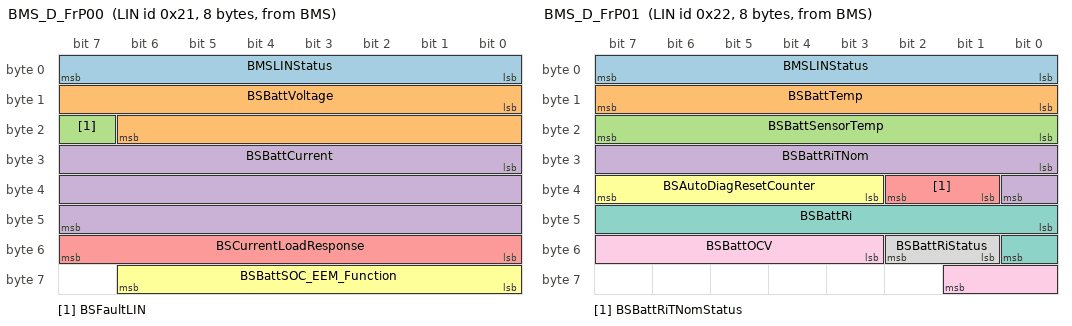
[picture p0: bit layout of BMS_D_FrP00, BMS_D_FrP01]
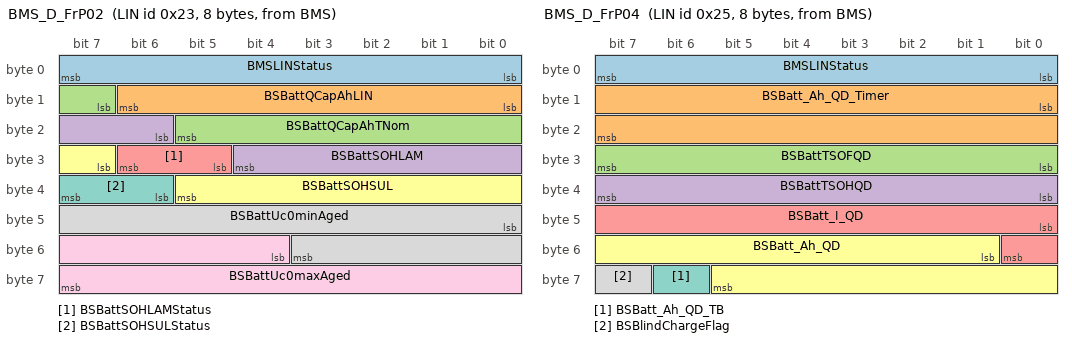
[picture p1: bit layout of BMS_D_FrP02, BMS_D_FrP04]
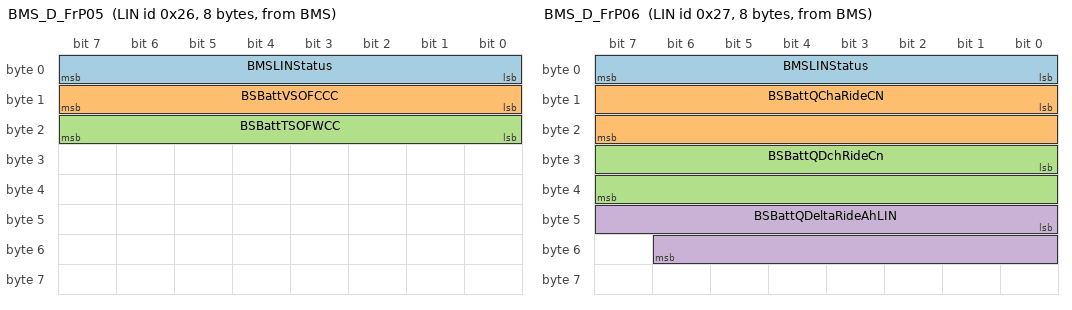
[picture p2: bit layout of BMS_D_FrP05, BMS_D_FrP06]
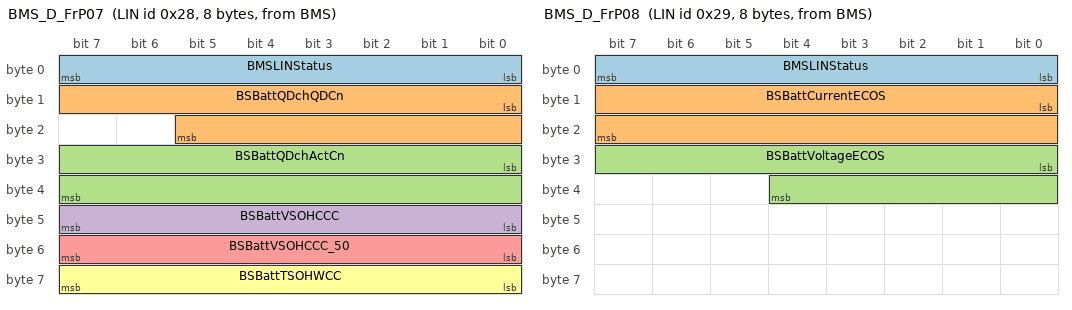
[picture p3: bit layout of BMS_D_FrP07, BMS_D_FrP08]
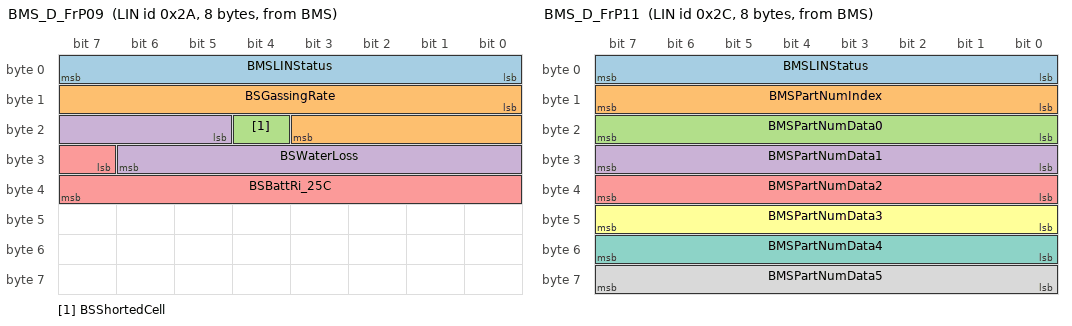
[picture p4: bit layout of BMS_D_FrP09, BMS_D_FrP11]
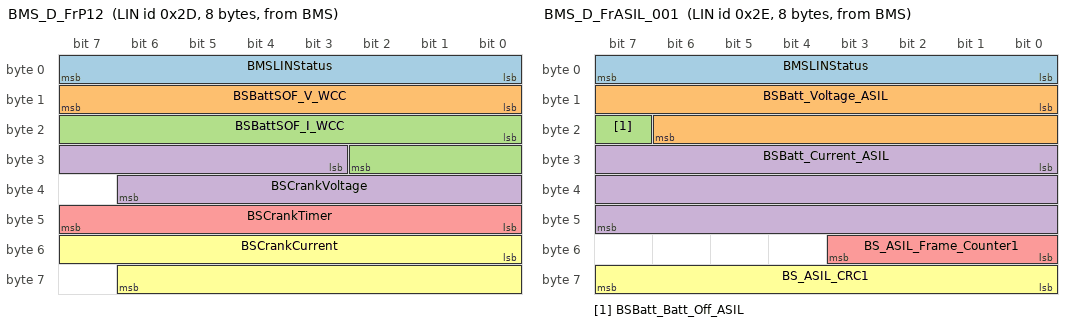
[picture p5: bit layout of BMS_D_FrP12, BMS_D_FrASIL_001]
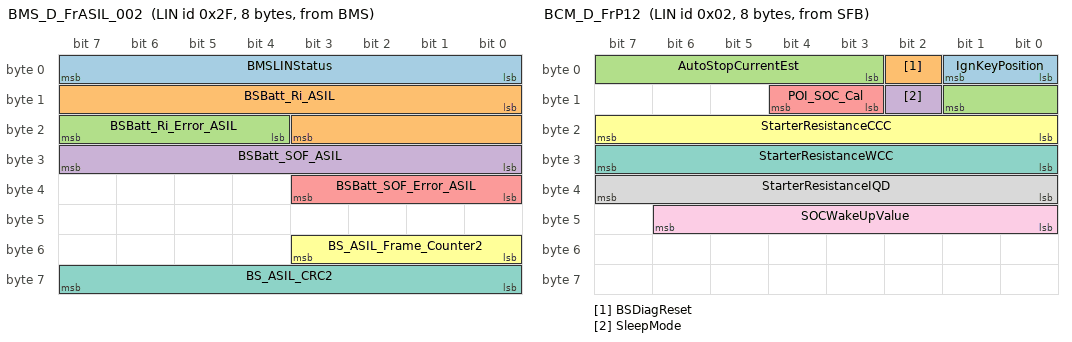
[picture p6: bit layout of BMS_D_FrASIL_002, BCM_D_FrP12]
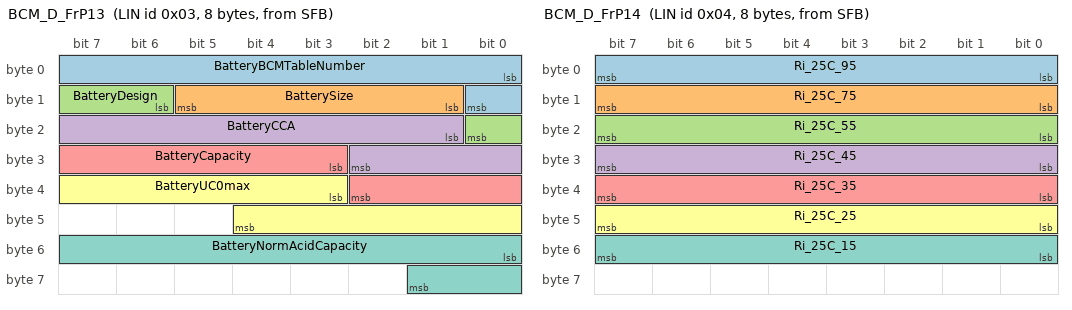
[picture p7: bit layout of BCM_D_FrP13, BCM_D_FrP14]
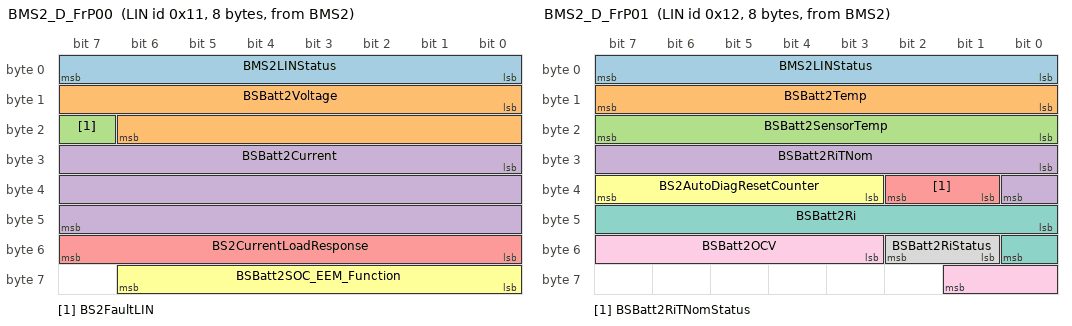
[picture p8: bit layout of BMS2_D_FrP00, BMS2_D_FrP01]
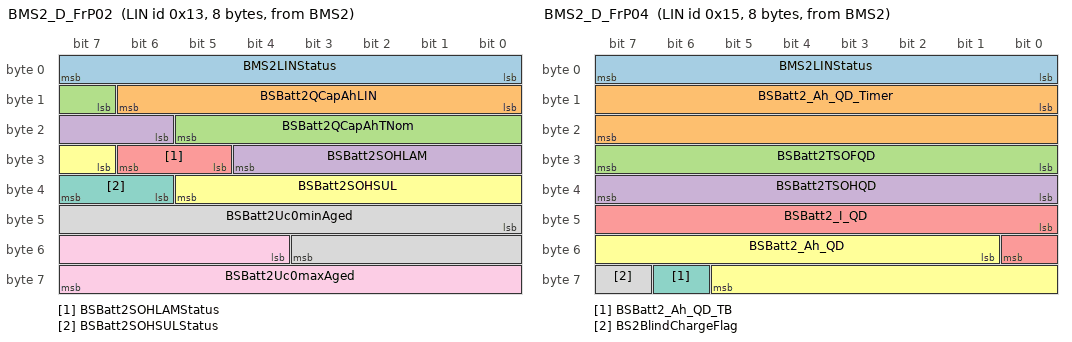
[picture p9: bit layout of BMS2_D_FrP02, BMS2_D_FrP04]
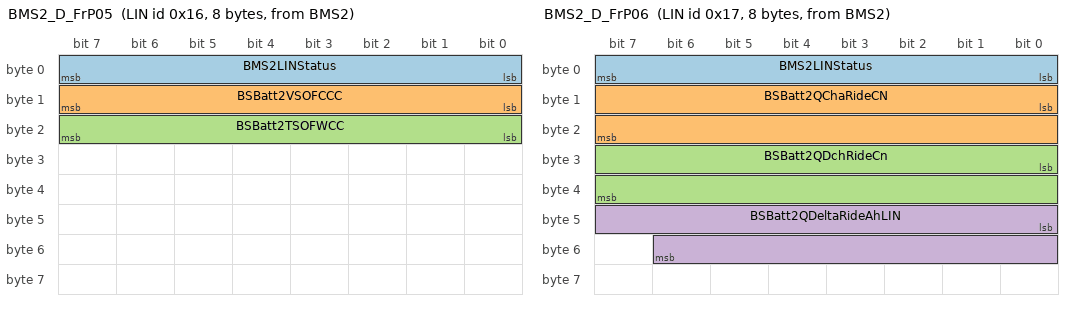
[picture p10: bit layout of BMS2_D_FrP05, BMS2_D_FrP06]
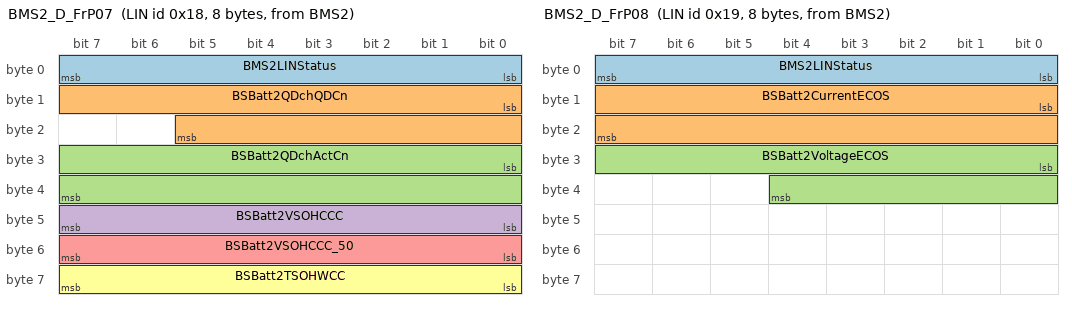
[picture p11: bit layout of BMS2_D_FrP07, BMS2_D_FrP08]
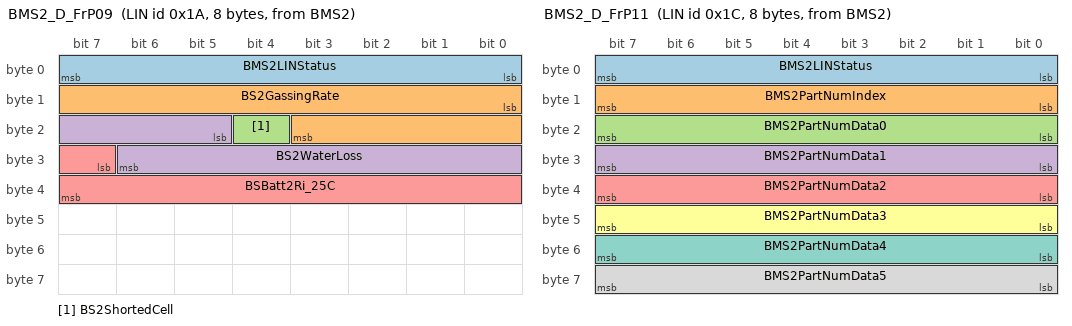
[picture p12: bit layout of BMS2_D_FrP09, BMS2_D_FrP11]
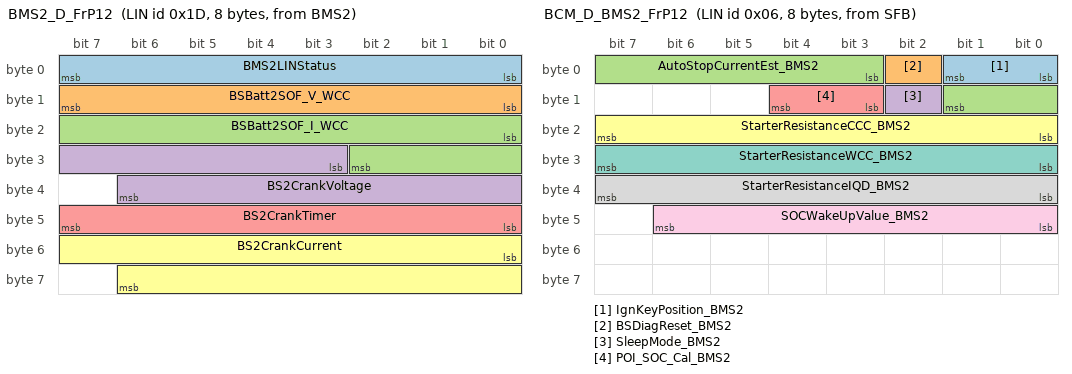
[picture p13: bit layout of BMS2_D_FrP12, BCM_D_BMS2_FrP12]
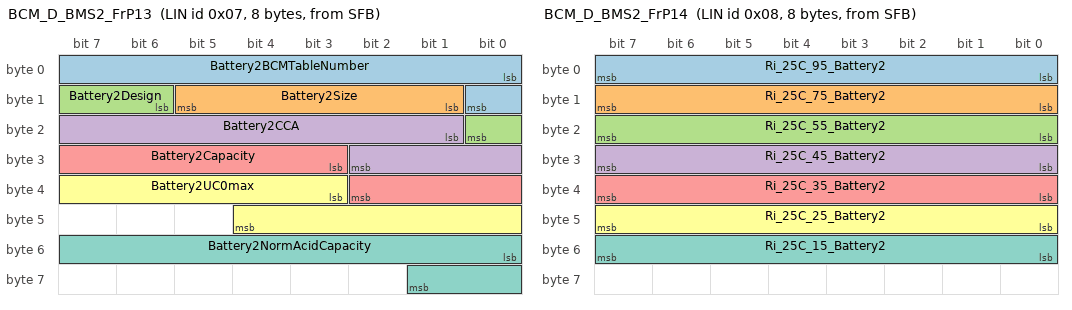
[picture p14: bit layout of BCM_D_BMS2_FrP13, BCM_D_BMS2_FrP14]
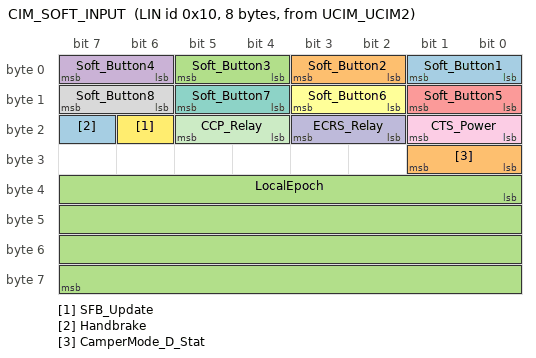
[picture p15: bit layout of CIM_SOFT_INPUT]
/* Azura Engineering Ltd */
/* All rights reserved */
/* Description: LIN Description file */
/* Date Created: 01-Nov-2023 */
/* Author: richard.harvie@azura-engineering.com */
/* Project: SFB Split Charge */
/* Release: Version 01 */
/* Configuration: SFB BMS2 BMS3 UCIM_UCIM2 */
/* Network: Private LIN BUS */
/* Original File: Ford BCM_LIN_D_Ckt_2021Apr08.ldf */

LIN_description_file;
LIN_protocol_version = "J2602_1_1.0";
LIN_language_version = "J2602_3_1.0";
LIN_speed = 10.417 kbps;

Nodes {
  Master: SFB, 10 ms, 0.05 ms;
  Slaves: BMS, BMS2, UCIM_UCIM2 ;
}

Signals {
   // Name, Size(bits), InitVal(raw), Publisher, Subscriber(s)

   /******** BMS -> Master ********/
   /* -= BMSLINStatus =- */
  BMSLINStatus: 8, 0, BMS, SFB ;
   /* -= Signals of BMS_D_FrP00 =- */
  BSBattVoltage: 15, 13120, BMS, SFB ;
  BSFaultLIN: 1, 0, BMS, SFB ;
  BSBattCurrent: 24, {0, 0, 2}, BMS, SFB ;
  BSCurrentLoadResponse: 8, 0, BMS, SFB ;
   /* -= Signals of BMS_D_FrP01 =- */
  BSBattTemp: 8, 60, BMS, SFB ;
  BSBattSensorTemp: 8, 60, BMS, SFB ;
  BSBattRiTNom: 9, 80, BMS, SFB ;
  BSBattRiTNomStatus: 2, 1, BMS, SFB ;
  BSAutoDiagResetCounter: 5, 0, BMS, SFB ;
  BSBattRi: 9, 80, BMS, SFB ;
  BSBattRiStatus: 2, 1, BMS, SFB ;
  BSBattOCV: 7, 104, BMS, SFB ;
   /* -= Signals of BMS_D_FrP02 =- */
  BSBattQCapAhLIN: 7, 60, BMS, SFB ;
  BSBattQCapAhTNom: 7, 60, BMS, SFB ;
  BSBattSOHLAM: 7, 0, BMS, SFB ;
  BSBattSOHLAMStatus: 2, 0, BMS, SFB ;
  BSBattSOHSUL: 7, 0, BMS, SFB ;
  BSBattSOHSULStatus: 2, 0, BMS, SFB ;
  BSBattUc0minAged: 12, 3036, BMS, SFB ;
  BSBattUc0maxAged: 12, 3297, BMS, SFB ;
   /* -= Signals of BMS_D_FrP03 =- */
  BSBattSOC_Actual: 7, 75, BMS, SFB ;
  BSBattSOC_EEM_Function: 7, 75, BMS, SFB ;
  BSBattSOCStatus: 2, 3, BMS, SFB ;
  BSBattLastSOCRecal: 8, 0, BMS, SFB ;
  BSBattSOCRecalUsed: 2, 3, BMS, SFB ;
  BSBattSOC_AhFlag: 1, 0, BMS, SFB ;
  BSBattSOC_ConsistencyFlag: 1, 0, BMS, SFB ;
  BSBattSOC_BlindChargeFlag: 1, 0, BMS, SFB ;
  BSBattSOC_PORFlag: 1, 1, BMS, SFB ;
  BSBattSOC_BSFaultFlag: 1, 0, BMS, SFB ;
  BSBattSOC_BatteryParameters: 1, 0, BMS, SFB ;
  BSBattSOC_BSDiagResetFlag: 1, 0, BMS, SFB ;
  BSBattSOC_TransportFlag: 1, 0, BMS, SFB ;
  BSStratification: 1, 0, BMS, SFB ;
  BSIcing: 1, 0, BMS, SFB ;
  BSConsistencyFault: 1, 0, BMS, SFB ;
  BSPowerOnJustOccured: 1, 1, BMS, SFB ;
  BSBattFullChargeDetected: 1, 0, BMS, SFB ;
  BSMode: 1, 0, BMS, SFB ;
  BSBattTimeInService: 12, 0, BMS, SFB ;
   /* -= Signals of BMS_D_FrP04 =- */
  BSBatt_Ah_QD_Timer: 16, 0, BMS, SFB ;
  BSBattTSOFQD: 8, 60, BMS, SFB ;
  BSBattTSOHQD: 8, 60, BMS, SFB ;
  BSBatt_I_QD: 9, 30, BMS, SFB ;
  BSBatt_Ah_QD: 13, 0, BMS, SFB ;
  BSBatt_Ah_QD_TB: 1, 0, BMS, SFB ;
  BSBlindChargeFlag: 1, 0, BMS, SFB ;
   /* -= Signals of BMS_D_FrP05 =- */
  BSBattVSOFCCC: 8, 176, BMS, SFB ;
  BSBattTSOFWCC: 8, 255, BMS, SFB ;
   /* -= Signals of BMS_D_FrP06 =- */
  BSBattQChaRideCN: 16, 0, BMS, SFB ;
  BSBattQDchRideCn: 16, 0, BMS, SFB ;
  BSBattQDeltaRideAhLIN: 15, 12800, BMS, SFB ;
   /* -= Signals of BMS_D_FrP07 =- */
  BSBattQDchQDCn: 14, 0, BMS, SFB ;
  BSBattQDchActCn: 16, 0, BMS, SFB ;
  BSBattVSOHCCC: 8, 176, BMS, SFB ;
  BSBattVSOHCCC_50: 8, 176, BMS, SFB ;
  BSBattTSOHWCC: 8, 255, BMS, SFB ;
   /* -= Signals of BMS_D_FrP08 =- */
  BSBattCurrentECOS: 16, 32768, BMS, SFB ;
  BSBattVoltageECOS: 13, 3280, BMS, SFB ;
   /* -= Signals of BMS_D_FrP09 =- */
  BSGassingRate: 12, 0, BMS, SFB ;
  BSShortedCell: 1, 0, BMS, SFB ;
  BSWaterLoss: 10, 0, BMS, SFB ;
  BSBattRi_25C: 9, 80, BMS, SFB ;
   /* -= Signals of BMS_D_FrP10 =- */
  BSBattKoLCurrent: 15, 32767, BMS, SFB ;
   /* -= Signals of BMS_D_FrP11 =- */
  BMSPartNumIndex: 8, 0, BMS, SFB ;
  BMSPartNumData0: 8, 0, BMS, SFB ;
  BMSPartNumData1: 8, 0, BMS, SFB ;
  BMSPartNumData2: 8, 0, BMS, SFB ;
  BMSPartNumData3: 8, 0, BMS, SFB ;
  BMSPartNumData4: 8, 0, BMS, SFB ;
  BMSPartNumData5: 8, 0, BMS, SFB ;
   /* -= Signals of BMS_D_FrP12 =- */
  BSBattSOF_V_WCC: 8, 0, BMS, SFB ;
  BSBattSOF_I_WCC: 11, 0, BMS, SFB ;
  BSCrankVoltage: 12, 0, BMS, SFB ;
  BSCrankTimer: 8, 0, BMS, SFB ;
  BSCrankCurrent: 15, 20800, BMS, SFB ;
  /* -= Signals of BMS_D_FrASIL_001 =- */
  BSBatt_Voltage_ASIL: 15, 0, BMS, SFB ;
  BSBatt_Batt_Off_ASIL: 1, 0, BMS, SFB ;
  BSBatt_Current_ASIL: 24, {0, 0, 2}, BMS, SFB ;
  BS_ASIL_Frame_Counter1: 4, 0, BMS, SFB ;
  BS_ASIL_CRC1: 8, 0, BMS, SFB ;
   /* -= Signals of BMS_D_FrASIL_002 =- */
  BSBatt_Ri_ASIL: 12, 0, BMS, SFB ;
  BSBatt_Ri_Error_ASIL: 4, 0, BMS, SFB ;
  BSBatt_SOF_ASIL: 8, 0, BMS, SFB ;
  BSBatt_SOF_Error_ASIL: 4, 0, BMS, SFB ;
  BS_ASIL_Frame_Counter2: 4, 0, BMS, SFB ;
  BS_ASIL_CRC2: 8, 0, BMS, SFB ;
   /******** Master -> BMS ********/
   /* -= Signals of BCM_D_FrP12 =- */
  IgnKeyPosition: 2, 0, SFB, BMS ;
  BSDiagReset: 1, 0, SFB, BMS ;
  AutoStopCurrentEst: 7, 0, SFB, BMS ;
  SleepMode: 1, 0, SFB, BMS ;
  POI_SOC_Cal: 2, 0, SFB, BMS ;
  StarterResistanceCCC: 8, 0, SFB, BMS ;
  StarterResistanceWCC: 8, 0, SFB, BMS ;
  StarterResistanceIQD: 8, 0, SFB, BMS ;
  SOCWakeUpValue: 7, 0, SFB, BMS ;
   /* -= Signals of BCM_D_FrP13 =- */
  BatteryBCMTableNumber: 9, 0, SFB, BMS ;
  BatterySize: 5, 0, SFB, BMS ;
  BatteryDesign: 3, 0, SFB, BMS ;
  BatteryCCA: 10, 0, SFB, BMS ;
  BatteryCapacity: 8, 0, SFB, BMS ;
  BatteryUC0max: 10, 0, SFB, BMS ;
  BatteryNormAcidCapacity: 10, 0, SFB, BMS ;
   /* -= Signals of BCM_D_FrP14 =- */
  Ri_25C_95: 8, 0, SFB, BMS ;
  Ri_25C_75: 8, 0, SFB, BMS ;
  Ri_25C_55: 8, 0, SFB, BMS ;
  Ri_25C_45: 8, 0, SFB, BMS ;
  Ri_25C_35: 8, 0, SFB, BMS ;
  Ri_25C_25: 8, 0, SFB, BMS ;
  Ri_25C_15: 8, 0, SFB, BMS ;
   /* -= Signals of BCM_D_FrP15 =- */
  CurrentLoadMagnitude: 10, 0, SFB, BMS ;
  CurrentLoadDuration: 10, 0, SFB, BMS ;

   /******** BMS2 -> Master ********/
   /* -= BMS2LINStatus =- */
  BMS2LINStatus: 8, 0, BMS2, SFB ;
   /* -= Signals of BMS2_D_FrP00 =- */
  BSBatt2Voltage: 15, 13120, BMS2, SFB ;
  BS2FaultLIN: 1, 0, BMS2, SFB ;
  BSBatt2Current: 24, {0, 0, 2}, BMS2, SFB ;
  BS2CurrentLoadResponse: 8, 0, BMS2, SFB ;
   /* -= Signals of BMS2_D_FrP01 =- */
  BSBatt2Temp: 8, 60, BMS2, SFB ;
  BSBatt2SensorTemp: 8, 60, BMS2, SFB ;
  BSBatt2RiTNom: 9, 80, BMS2, SFB ;
  BSBatt2RiTNomStatus: 2, 1, BMS2, SFB ;
  BS2AutoDiagResetCounter: 5, 0, BMS2, SFB ;
  BSBatt2Ri: 9, 80, BMS2, SFB ;
  BSBatt2RiStatus: 2, 1, BMS2, SFB ;
  BSBatt2OCV: 7, 104, BMS2, SFB ;
   /* -= Signals of BMS2_D_FrP02 =- */
  BSBatt2QCapAhLIN: 7, 60, BMS2, SFB ;
  BSBatt2QCapAhTNom: 7, 60, BMS2, SFB ;
  BSBatt2SOHLAM: 7, 0, BMS2, SFB ;
  BSBatt2SOHLAMStatus: 2, 0, BMS2, SFB ;
  BSBatt2SOHSUL: 7, 0, BMS2, SFB ;
  BSBatt2SOHSULStatus: 2, 0, BMS2, SFB ;
  BSBatt2Uc0minAged: 12, 3036, BMS2, SFB ;
  BSBatt2Uc0maxAged: 12, 3297, BMS2, SFB ;
   /* -= Signals of BMS2_D_FrP03 =- */
  BSBatt2SOC_Actual: 7, 75, BMS2, SFB ;
  BSBatt2SOC_EEM_Function: 7, 75, BMS2, SFB ;
  BSBatt2SOCStatus: 2, 3, BMS2, SFB ;
  BSBatt2LastSOCRecal: 8, 0, BMS2, SFB ;
  BSBatt2SOCRecalUsed: 2, 3, BMS2, SFB ;
  BSBatt2SOC_AhFlag: 1, 0, BMS2, SFB ;
  BSBatt2SOC_ConsistencyFlag: 1, 0, BMS2, SFB ;
  BSBatt2SOC_BlindChargeFlag: 1, 0, BMS2, SFB ;
  BSBatt2SOC_PORFlag: 1, 1, BMS2, SFB ;
  BSBatt2SOC_BSFaultFlag: 1, 0, BMS2, SFB ;
  BSBatt2SOC_BatteryParameters: 1, 0, BMS2, SFB ;
  BSBatt2SOC_BSDiagResetFlag: 1, 0, BMS2, SFB ;
  BSBatt2SOC_TransportFlag: 1, 0, BMS2, SFB ;
  BS2Stratification: 1, 0, BMS2, SFB ;
  BS2Icing: 1, 0, BMS2, SFB ;
  BS2ConsistencyFault: 1, 0, BMS2, SFB ;
  BS2PowerOnJustOccured: 1, 1, BMS2, SFB ;
  BSBatt2FullChargeDetected: 1, 0, BMS2, SFB ;
  BS2Mode: 1, 0, BMS2, SFB ;
  BSBatt2TimeInService: 12, 0, BMS2, SFB ;
   /* -= Signals of BMS2_D_FrP04 =- */
  BSBatt2_Ah_QD_Timer: 16, 0, BMS2, SFB ;
  BSBatt2TSOFQD: 8, 60, BMS2, SFB ;
  BSBatt2TSOHQD: 8, 60, BMS2, SFB ;
  BSBatt2_I_QD: 9, 30, BMS2, SFB ;
  BSBatt2_Ah_QD: 13, 0, BMS2, SFB ;
  BSBatt2_Ah_QD_TB: 1, 0, BMS2, SFB ;
  BS2BlindChargeFlag: 1, 0, BMS2, SFB ;
   /* -= Signals of BMS2_D_FrP05 =- */
  BSBatt2VSOFCCC: 8, 176, BMS2, SFB ;
  BSBatt2TSOFWCC: 8, 255, BMS2, SFB ;
   /* -= Signals of BMS2_D_FrP06 =- */
  BSBatt2QChaRideCN: 16, 0, BMS2, SFB ;
  BSBatt2QDchRideCn: 16, 0, BMS2, SFB ;
  BSBatt2QDeltaRideAhLIN: 15, 12800, BMS2, SFB ;
   /* -= Signals of BMS2_D_FrP07 =- */
  BSBatt2QDchQDCn: 14, 0, BMS2, SFB ;
  BSBatt2QDchActCn: 16, 0, BMS2, SFB ;
  BSBatt2VSOHCCC: 8, 176, BMS2, SFB ;
  BSBatt2VSOHCCC_50: 8, 176, BMS2, SFB ;
  BSBatt2TSOHWCC: 8, 255, BMS2, SFB ;
   /* -= Signals of BMS2_D_FrP08 =- */
  BSBatt2CurrentECOS: 16, 32768, BMS2, SFB ;
  BSBatt2VoltageECOS: 13, 3280, BMS2, SFB ;
   /* -= Signals of BMS2_D_FrP09 =- */
  BS2GassingRate: 12, 0, BMS2, SFB ;
  BS2ShortedCell: 1, 0, BMS2, SFB ;
  BS2WaterLoss: 10, 0, BMS2, SFB ;
  BSBatt2Ri_25C: 9, 80, BMS2, SFB ;
   /* -= Signals of BMS2_D_FrP10 =- */
  BSBatt2KoLCurrent: 15, 32767, BMS2, SFB ;
   /* -= Signals of BMS2_D_FrP11 =- */
  BMS2PartNumIndex: 8, 0, BMS2, SFB ;
  BMS2PartNumData0: 8, 0, BMS2, SFB ;
  BMS2PartNumData1: 8, 0, BMS2, SFB ;
  BMS2PartNumData2: 8, 0, BMS2, SFB ;
  BMS2PartNumData3: 8, 0, BMS2, SFB ;
  BMS2PartNumData4: 8, 0, BMS2, SFB ;
  BMS2PartNumData5: 8, 0, BMS2, SFB ;
   /* -= Signals of BMS2_D_FrP12 =- */
  BSBatt2SOF_V_WCC: 8, 0, BMS2, SFB ;
  BSBatt2SOF_I_WCC: 11, 0, BMS2, SFB ;
  BS2CrankVoltage: 12, 0, BMS2, SFB ;
  BS2CrankTimer: 8, 0, BMS2, SFB ;
  BS2CrankCurrent: 15, 20800, BMS2, SFB ;

   /******** Master -> BMS2 ********/
   /* -= Signals of BCM_D_BMS2_FrP12 =- */
  IgnKeyPosition_BMS2: 2, 0, SFB, BMS2 ;
  BSDiagReset_BMS2: 1, 0, SFB, BMS2 ;
  AutoStopCurrentEst_BMS2: 7, 0, SFB, BMS2 ;
  SleepMode_BMS2: 1, 0, SFB, BMS2 ;
  POI_SOC_Cal_BMS2: 2, 0, SFB, BMS2 ;
  StarterResistanceCCC_BMS2: 8, 0, SFB, BMS2 ;
  StarterResistanceWCC_BMS2: 8, 0, SFB, BMS2 ;
  StarterResistanceIQD_BMS2: 8, 0, SFB, BMS2 ;
  SOCWakeUpValue_BMS2: 7, 0, SFB, BMS2 ;
   /* -= Signals of BCM_D_BMS2_FrP13 =- */
  Battery2BCMTableNumber: 9, 0, SFB, BMS2 ;
  Battery2Size: 5, 0, SFB, BMS2 ;
  Battery2Design: 3, 0, SFB, BMS2 ;
  Battery2CCA: 10, 0, SFB, BMS2 ;
  Battery2Capacity: 8, 0, SFB, BMS2 ;
  Battery2UC0max: 10, 0, SFB, BMS2 ;
  Battery2NormAcidCapacity: 10, 0, SFB, BMS2 ;
   /* -= Signals of BCM_D_BMS2_FrP14 =- */
  Ri_25C_95_Battery2: 8, 0, SFB, BMS2 ;
  Ri_25C_75_Battery2: 8, 0, SFB, BMS2 ;
  Ri_25C_55_Battery2: 8, 0, SFB, BMS2 ;
  Ri_25C_45_Battery2: 8, 0, SFB, BMS2 ;
  Ri_25C_35_Battery2: 8, 0, SFB, BMS2 ;
  Ri_25C_25_Battery2: 8, 0, SFB, BMS2 ;
  Ri_25C_15_Battery2: 8, 0, SFB, BMS2 ;
   /* -= Signals of BCM_D_FrP15 =- */
  CurrentLoadMagnitude_BMS2: 10, 0, SFB, BMS2 ;
  CurrentLoadDuration_BMS2: 10, 0, SFB, BMS2 ;

  /******** UCIM_UCIM2 -> Master ********/
  /* -= Signals of CIM_SOFT_INPUT =- */
  Soft_Button1: 2, 0, UCIM_UCIM2, SFB ;
  Soft_Button2: 2, 0, UCIM_UCIM2, SFB ;
  Soft_Button3: 2, 0, UCIM_UCIM2, SFB ;
  Soft_Button4: 2, 0, UCIM_UCIM2, SFB ;
  Soft_Button5: 2, 0, UCIM_UCIM2, SFB ;
  Soft_Button6: 2, 0, UCIM_UCIM2, SFB ;
  Soft_Button7: 2, 0, UCIM_UCIM2, SFB ;
  Soft_Button8: 2, 0, UCIM_UCIM2, SFB ;
  CTS_Power: 2, 0, UCIM_UCIM2, SFB ;
  ECRS_Relay: 2, 0, UCIM_UCIM2, SFB ;
  CCP_Relay: 2, 0, UCIM_UCIM2, SFB ;
  SFB_Update: 1, 0, UCIM_UCIM2, SFB ;
  Handbrake: 1, 0, UCIM_UCIM2, SFB ;
  CamperMode_D_Stat: 2, 0, UCIM_UCIM2, SFB ;
  LocalEpoch: 32, 0, UCIM_UCIM2, SFB ;

   /* -= Signals of Slave_Error_Response_UCIM_UCIM2 =- */
  UCIM_UCIM2_error_response_camper_st: 4, 0, UCIM_UCIM2, SFB ;

   /******** Master --> UCIM_UCIM2 ********/
   /* -= Signals of SFB_STATUS =- */
  FuseState1: 2, 0, SFB, UCIM_UCIM2 ;
  FuseState2: 2, 0, SFB, UCIM_UCIM2 ;
  FuseState3: 2, 0, SFB, UCIM_UCIM2 ;
  FuseState4: 2, 0, SFB, UCIM_UCIM2 ;
  FuseState5: 2, 0, SFB, UCIM_UCIM2 ;
  FuseState6: 2, 0, SFB, UCIM_UCIM2 ;
  FuseState7: 2, 0, SFB, UCIM_UCIM2 ;
  FuseState8: 2, 0, SFB, UCIM_UCIM2 ;
  InputPin1: 1, 0, SFB, UCIM_UCIM2 ;
  InputPin2: 1, 0, SFB, UCIM_UCIM2 ;
  InputPin3: 1, 0, SFB, UCIM_UCIM2 ;
  InputPin4: 1, 0, SFB, UCIM_UCIM2 ;
  InputPin5: 1, 0, SFB, UCIM_UCIM2 ;
  InputPin6: 1, 0, SFB, UCIM_UCIM2 ;
  InputPin7: 1, 0, SFB, UCIM_UCIM2 ;
  InputPin8: 1, 0, SFB, UCIM_UCIM2 ;
  BatterySocAux1: 7, 0, SFB, UCIM_UCIM2 ;
  BatterySocAux1Source: 1, 0, SFB, UCIM_UCIM2 ;
  BatterySocAux2: 7, 0, SFB, UCIM_UCIM2 ;
  BatterySocAux2Source: 1, 0, SFB, UCIM_UCIM2 ;
  EcrmRelayState: 1, 0, SFB, UCIM_UCIM2 ;
  CcpRelayState: 1, 0, SFB, UCIM_UCIM2 ;
  CamperMode_B_RQ : 1, 0, SFB, UCIM_UCIM2 ;
  SplitChargeRule: 8, 0, SFB, UCIM_UCIM2 ;
}

Frames {
   /******** BMS -> Master ********/
   BMS_D_FrP00: 0x21, BMS, 8
   {
    BMSLINStatus, 0 ;
    BSBattVoltage, 8 ;
    BSFaultLIN, 23 ;
    BSBattCurrent, 24 ;
    BSCurrentLoadResponse, 48 ;
    BSBattSOC_EEM_Function, 56 ;
  }
   BMS_D_FrP01: 0x22, BMS, 8
   {
    BMSLINStatus, 0 ;
    BSBattTemp, 8 ;
    BSBattSensorTemp, 16 ;
    BSBattRiTNom, 24 ;
    BSBattRiTNomStatus, 33 ;
    BSAutoDiagResetCounter, 35 ;
    BSBattRi, 40 ;
    BSBattRiStatus, 49 ;
    BSBattOCV, 51 ;
  }
   BMS_D_FrP02: 0x23, BMS, 8
   {
    BMSLINStatus, 0 ;
    BSBattQCapAhLIN, 8 ;
    BSBattQCapAhTNom, 15 ;
    BSBattSOHLAM, 22 ;
    BSBattSOHLAMStatus, 29 ;
    BSBattSOHSUL, 31 ;
    BSBattSOHSULStatus, 38 ;
    BSBattUc0minAged, 40 ;
    BSBattUc0maxAged, 52 ;
  }
   BMS_D_FrP03: 0x24, BMS, 8
   {
    BMSLINStatus, 0 ;
    BSBattSOC_Actual, 8 ;
    BSBattSOC_EEM_Function, 15 ;
    BSBattSOCStatus, 22 ;
    BSBattLastSOCRecal, 24 ;
    BSBattSOCRecalUsed, 32 ;
    BSBattSOC_AhFlag, 34 ;
    BSBattSOC_ConsistencyFlag, 35 ;
    BSBattSOC_BlindChargeFlag, 36 ;
    BSBattSOC_PORFlag, 37 ;
    BSBattSOC_BSFaultFlag, 38 ;
    BSBattSOC_BatteryParameters, 39 ;
    BSBattSOC_BSDiagResetFlag, 40 ;
    BSBattSOC_TransportFlag, 41 ;
    BSStratification, 42 ;
    BSIcing, 43 ;
    BSConsistencyFault, 44 ;
    BSPowerOnJustOccured, 45 ;
    BSBattFullChargeDetected, 46 ;
    BSMode, 47 ;
    BSBattTimeInService, 48 ;
  }
   BMS_D_FrP04: 0x25, BMS, 8
   {
    BMSLINStatus, 0 ;
    BSBatt_Ah_QD_Timer, 8 ;
    BSBattTSOFQD, 24 ;
    BSBattTSOHQD, 32 ;
    BSBatt_I_QD, 40 ;
    BSBatt_Ah_QD, 49 ;
    BSBatt_Ah_QD_TB, 62 ;
    BSBlindChargeFlag, 63 ;
  }
   BMS_D_FrP05: 0x26, BMS, 8
   {
    BMSLINStatus, 0 ;
    BSBattVSOFCCC, 8 ;
    BSBattTSOFWCC, 16 ;
  }
   BMS_D_FrP06: 0x27, BMS, 8
   {
    BMSLINStatus, 0 ;
    BSBattQChaRideCN, 8 ;
    BSBattQDchRideCn, 24 ;
    BSBattQDeltaRideAhLIN, 40 ;
  }
   BMS_D_FrP07: 0x28, BMS, 8
   {
    BMSLINStatus, 0 ;
    BSBattQDchQDCn, 8 ;
    BSBattQDchActCn, 24 ;
    BSBattVSOHCCC, 40 ;
    BSBattVSOHCCC_50, 48 ;
    BSBattTSOHWCC, 56 ;
  }
   BMS_D_FrP08: 0x29, BMS, 8
   {
    BMSLINStatus, 0 ;
    BSBattCurrentECOS, 8 ;
    BSBattVoltageECOS, 24 ;
  }
   BMS_D_FrP09: 0x2A, BMS, 8
   {
    BMSLINStatus, 0 ;
    BSGassingRate, 8 ;
    BSShortedCell, 20 ;
    BSWaterLoss, 21 ;
    BSBattRi_25C, 31 ;
  }
   BMS_D_FrP10: 0x2B, BMS, 8
   {
    BSBattKoLCurrent, 0 ;
  }
   BMS_D_FrP11: 0x2C, BMS, 8
   {
    BMSLINStatus, 0 ;
    BMSPartNumIndex, 8 ;
    BMSPartNumData0, 16 ;
    BMSPartNumData1, 24 ;
    BMSPartNumData2, 32 ;
    BMSPartNumData3, 40 ;
    BMSPartNumData4, 48 ;
    BMSPartNumData5, 56 ;
  }
   BMS_D_FrP12: 0x2D, BMS, 8
   {
    BMSLINStatus, 0 ;
    BSBattSOF_V_WCC, 8 ;
    BSBattSOF_I_WCC, 16 ;
    BSCrankVoltage, 27 ;
    BSCrankTimer, 40 ;
    BSCrankCurrent, 48 ;
  }
   BMS_D_FrASIL_001: 0x2E, BMS, 8
   {
    BMSLINStatus, 0 ;
    BSBatt_Voltage_ASIL, 8 ;
    BSBatt_Batt_Off_ASIL, 23 ;
    BSBatt_Current_ASIL, 24 ;
    BS_ASIL_Frame_Counter1, 48 ;
    BS_ASIL_CRC1, 56 ;
  }
   BMS_D_FrASIL_002: 0x2F, BMS, 8
   {
    BMSLINStatus, 0 ;
    BSBatt_Ri_ASIL, 8 ;
    BSBatt_Ri_Error_ASIL, 20 ;
    BSBatt_SOF_ASIL, 24 ;
    BSBatt_SOF_Error_ASIL, 32 ;
    BS_ASIL_Frame_Counter2, 48 ;
    BS_ASIL_CRC2, 56 ;
  }
   /******** Master -> BMS ********/
   BCM_D_FrP12: 0x02, SFB, 8
   {
    IgnKeyPosition, 0 ;
    BSDiagReset, 2 ;
    AutoStopCurrentEst, 3 ;
    SleepMode, 10 ;
    POI_SOC_Cal, 11 ;
    StarterResistanceCCC, 16 ;
    StarterResistanceWCC, 24 ;
    StarterResistanceIQD, 32 ;
    SOCWakeUpValue, 40 ;
  }

   BCM_D_FrP13: 0x03, SFB, 8
   {
    BatteryBCMTableNumber, 0 ;
    BatterySize, 9 ;
    BatteryDesign, 14 ;
    BatteryCCA, 17 ;
    BatteryCapacity, 27 ;
    BatteryUC0max, 35 ;
    BatteryNormAcidCapacity, 48 ;
  }
   BCM_D_FrP14: 0x04, SFB, 8
   {
    Ri_25C_95, 0 ;
    Ri_25C_75, 8 ;
    Ri_25C_55, 16 ;
    Ri_25C_45, 24 ;
    Ri_25C_35, 32 ;
    Ri_25C_25, 40 ;
    Ri_25C_15, 48 ;
  }
   BCM_D_FrP15: 0x05, SFB, 8
   {
    CurrentLoadMagnitude, 0 ;
    CurrentLoadDuration, 10 ;
  }

   /******** XCP Communication ********/
   /* XCP_Request: 0x3A, CANape, 8 RESERVED for Supplier Implementation */
   /* XCP_Response: 0x3B, BMS, 8 RESERVED for Supplier Implementation */

   /******** BMS2 -> Master ********/
   BMS2_D_FrP00: 0x11, BMS2, 8
   {
    BMS2LINStatus, 0 ;
    BSBatt2Voltage, 8 ;
    BS2FaultLIN, 23 ;
    BSBatt2Current, 24 ;
    BS2CurrentLoadResponse, 48 ;
    BSBatt2SOC_EEM_Function, 56 ;
  }
   BMS2_D_FrP01: 0x12, BMS2, 8
   {
    BMS2LINStatus, 0 ;
    BSBatt2Temp, 8 ;
    BSBatt2SensorTemp, 16 ;
    BSBatt2RiTNom, 24 ;
    BSBatt2RiTNomStatus, 33 ;
    BS2AutoDiagResetCounter, 35 ;
    BSBatt2Ri, 40 ;
    BSBatt2RiStatus, 49 ;
    BSBatt2OCV, 51 ;
  }
   BMS2_D_FrP02: 0x13, BMS2, 8
   {
    BMS2LINStatus, 0 ;
    BSBatt2QCapAhLIN, 8 ;
    BSBatt2QCapAhTNom, 15 ;
    BSBatt2SOHLAM, 22 ;
    BSBatt2SOHLAMStatus, 29 ;
    BSBatt2SOHSUL, 31 ;
    BSBatt2SOHSULStatus, 38 ;
    BSBatt2Uc0minAged, 40 ;
    BSBatt2Uc0maxAged, 52 ;
  }
   BMS2_D_FrP03: 0x14, BMS2, 8
   {
    BMS2LINStatus, 0 ;
    BSBatt2SOC_Actual, 8 ;
    BSBatt2SOC_EEM_Function, 15 ;
    BSBatt2SOCStatus, 22 ;
    BSBatt2LastSOCRecal, 24 ;
    BSBatt2SOCRecalUsed, 32 ;
    BSBatt2SOC_AhFlag, 34 ;
    BSBatt2SOC_ConsistencyFlag, 35 ;
    BSBatt2SOC_BlindChargeFlag, 36 ;
    BSBatt2SOC_PORFlag, 37 ;
    BSBatt2SOC_BSFaultFlag, 38 ;
    BSBatt2SOC_BatteryParameters, 39 ;
    BSBatt2SOC_BSDiagResetFlag, 40 ;
    BSBatt2SOC_TransportFlag, 41 ;
    BS2Stratification, 42 ;
    BS2Icing, 43 ;
    BS2ConsistencyFault, 44 ;
    BS2PowerOnJustOccured, 45 ;
    BSBatt2FullChargeDetected, 46 ;
    BS2Mode, 47 ;
    BSBatt2TimeInService, 48 ;
  }
   BMS2_D_FrP04: 0x15, BMS2, 8
   {
    BMS2LINStatus, 0 ;
    BSBatt2_Ah_QD_Timer, 8 ;
    BSBatt2TSOFQD, 24 ;
    BSBatt2TSOHQD, 32 ;
    BSBatt2_I_QD, 40 ;
    BSBatt2_Ah_QD, 49 ;
    BSBatt2_Ah_QD_TB, 62 ;
    BS2BlindChargeFlag, 63 ;
  }
   BMS2_D_FrP05: 0x16, BMS2, 8
   {
    BMS2LINStatus, 0 ;
    BSBatt2VSOFCCC, 8 ;
    BSBatt2TSOFWCC, 16 ;
  }
   BMS2_D_FrP06: 0x17, BMS2, 8
   {
    BMS2LINStatus, 0 ;
    BSBatt2QChaRideCN, 8 ;
    BSBatt2QDchRideCn, 24 ;
    BSBatt2QDeltaRideAhLIN, 40 ;
  }
   BMS2_D_FrP07: 0x18, BMS2, 8
   {
    BMS2LINStatus, 0 ;
    BSBatt2QDchQDCn, 8 ;
    BSBatt2QDchActCn, 24 ;
    BSBatt2VSOHCCC, 40 ;
    BSBatt2VSOHCCC_50, 48 ;
    BSBatt2TSOHWCC, 56 ;
  }
   BMS2_D_FrP08: 0x19, BMS2, 8
   {
    BMS2LINStatus, 0 ;
    BSBatt2CurrentECOS, 8 ;
    BSBatt2VoltageECOS, 24 ;
  }
   BMS2_D_FrP09: 0x1A, BMS2, 8
   {
    BMS2LINStatus, 0 ;
    BS2GassingRate, 8 ;
    BS2ShortedCell, 20 ;
    BS2WaterLoss, 21 ;
    BSBatt2Ri_25C, 31 ;
  }
   BMS2_D_FrP10: 0x1B, BMS2, 8
   {
    BSBatt2KoLCurrent, 0 ;
  }
   BMS2_D_FrP11: 0x1C, BMS2, 8
   {
    BMS2LINStatus, 0 ;
    BMS2PartNumIndex, 8 ;
    BMS2PartNumData0, 16 ;
    BMS2PartNumData1, 24 ;
    BMS2PartNumData2, 32 ;
    BMS2PartNumData3, 40 ;
    BMS2PartNumData4, 48 ;
    BMS2PartNumData5, 56 ;
  }
   BMS2_D_FrP12: 0x1D, BMS2, 8
   {
    BMS2LINStatus, 0 ;
    BSBatt2SOF_V_WCC, 8 ;
    BSBatt2SOF_I_WCC, 16 ;
    BS2CrankVoltage, 27 ;
    BS2CrankTimer, 40 ;
    BS2CrankCurrent, 48 ;
  }

   /******** Master -> BMS2 ********/
   BCM_D_BMS2_FrP12: 0x06, SFB, 8
   {
    IgnKeyPosition_BMS2, 0 ;
    BSDiagReset_BMS2, 2 ;
    AutoStopCurrentEst_BMS2, 3 ;
    SleepMode_BMS2, 10 ;
    POI_SOC_Cal_BMS2, 11 ;
    StarterResistanceCCC_BMS2, 16 ;
    StarterResistanceWCC_BMS2, 24 ;
    StarterResistanceIQD_BMS2, 32 ;
    SOCWakeUpValue_BMS2, 40 ;
  }

   BCM_D_BMS2_FrP13: 0x07, SFB, 8
   {
    Battery2BCMTableNumber, 0 ;
    Battery2Size, 9 ;
    Battery2Design, 14 ;
    Battery2CCA, 17 ;
    Battery2Capacity, 27 ;
    Battery2UC0max, 35 ;
    Battery2NormAcidCapacity, 48 ;
  }
   BCM_D_BMS2_FrP14: 0x08, SFB, 8
   {
    Ri_25C_95_Battery2, 0 ;
    Ri_25C_75_Battery2, 8 ;
    Ri_25C_55_Battery2, 16 ;
    Ri_25C_45_Battery2, 24 ;
    Ri_25C_35_Battery2, 32 ;
    Ri_25C_25_Battery2, 40 ;
    Ri_25C_15_Battery2, 48 ;
  }
   BCM_D_BMS2_FrP15: 0x09, SFB, 8
   {
    CurrentLoadMagnitude_BMS2, 0 ;
    CurrentLoadDuration_BMS2, 10 ;
  }

   /******** XCP Communication ********/
   /* XCP_Request: 0x3A, CANape, 8 RESERVED for Supplier Implementation */
   /* XCP_Response: 0x3B, BMS2, 8 RESERVED for Supplier Implementation */

   /******** UCIM_UCIM2 -> Master ********/
   CIM_SOFT_INPUT: 0x10, UCIM_UCIM2, 8
   {
     Soft_Button1, 0;
   Soft_Button2, 2;
   Soft_Button3, 4;
   Soft_Button4, 6;
   Soft_Button5, 8;
   Soft_Button6, 10;
   Soft_Button7, 12;
   Soft_Button8, 14;
   CTS_Power, 16;
   ECRS_Relay, 18;
   CCP_Relay, 20;
   SFB_Update, 22;
   Handbrake, 23;
   CamperMode_D_Stat, 24;
   LocalEpoch, 32;
   }

   Slave_Error_Response_UCIM_UCIM2: 0x1E, UCIM_UCIM2, 8
   {
     UCIM_UCIM2_error_response_camper_st, 0;
   }

   /******** Master --> UCIM_UCIM2 ********/
   SFB_STATUS: 0x01, SFB, 8
   {
     FuseState1, 0;
   FuseState2, 2;
   FuseState3, 4;
   FuseState4, 6;
   FuseState5, 8;
   FuseState6, 10;
   FuseState7, 12;
   FuseState8, 14;
   InputPin1, 16;
   InputPin2, 17;
   InputPin3, 18;
   InputPin4, 19;
   InputPin5, 20;
   InputPin6, 21;
   InputPin7, 22;
   InputPin8, 23;
   BatterySocAux1, 24;
   BatterySocAux1Source, 31;
   BatterySocAux2, 32;
   BatterySocAux2Source, 39;
   EcrmRelayState, 40;
   CcpRelayState, 41;
   CamperMode_B_RQ, 42;
   SplitChargeRule, 56;
   }
}

/* Diagnostic_frames */
/* MasterReq: 0x3C RESERVED for Supplier Implementation */

/* SlaveResp: 0x3D RESERVED for Supplier Implementation */

Node_attributes {
  BMS{
    LIN_protocol = "J2602_1_1.0" ;
    configured_NAD = 0x68 ;
    product_id = 0x0040, 0x7001, 0xFF; /* Supplier ID (0x0040 = ETAS), Function ID (0x7001 = EBS) */
    response_error = BMSLINStatus ;
    P2_min = 10 ms ;
    ST_min = 10 ms ;
    configurable_frames {
      BMS_D_FrP00 = 0x21 ;
      BMS_D_FrP01 = 0x22 ;
      BMS_D_FrP02 = 0x23 ;
      BMS_D_FrP03 = 0x24 ;
      BMS_D_FrP04 = 0x25 ;
      BMS_D_FrP05 = 0x26 ;
      BMS_D_FrP06 = 0x27 ;
      BMS_D_FrP07 = 0x28 ;
      BMS_D_FrP08 = 0x29 ;
      BMS_D_FrP09 = 0x2A ;
      BMS_D_FrP10 = 0x2B ;
      BMS_D_FrP11 = 0x2C ;
      BMS_D_FrP12 = 0x2D ;
      BCM_D_FrP12 = 0x02 ;
      BCM_D_FrP13 = 0x03 ;
      BCM_D_FrP14 = 0x04 ;
      BCM_D_FrP15 = 0x05 ;
      BMS_D_FrASIL_001 = 0x2E ;
      BMS_D_FrASIL_002 = 0x2F ;
    }
    response_tolerance = 40 % ;
  }

  BMS2{
    LIN_protocol = "J2602_1_1.0" ;
    configured_NAD = 0x6A ;
    product_id = 0x0040, 0x7001, 0xFF; /* Supplier ID (0x0040 = ETAS), Function ID (0x7001 = EBS) */
    response_error = BMS2LINStatus ;
    P2_min = 10 ms ;
    ST_min = 10 ms ;
    configurable_frames {
      BMS2_D_FrP00 = 0x11 ;
      BMS2_D_FrP01 = 0x12 ;
      BMS2_D_FrP02 = 0x13 ;
      BMS2_D_FrP03 = 0x14 ;
      BMS2_D_FrP04 = 0x15 ;
      BMS2_D_FrP05 = 0x16 ;
      BMS2_D_FrP06 = 0x17 ;
      BMS2_D_FrP07 = 0x18 ;
      BMS2_D_FrP08 = 0x19 ;
      BMS2_D_FrP09 = 0x1A ;
      BMS2_D_FrP10 = 0x1B ;
      BMS2_D_FrP11 = 0x1C ;
      BMS2_D_FrP12 = 0x1D ;
      BCM_D_BMS2_FrP12 = 0x06 ;
      BCM_D_BMS2_FrP13 = 0x07 ;
      BCM_D_BMS2_FrP14 = 0x08 ;
      BCM_D_BMS2_FrP15 = 0x09 ;
    }
    response_tolerance = 40 % ;
  }

  UCIM_UCIM2{
    LIN_protocol = "J2602_1_1.0" ;
    configured_NAD = 0x6B ; /* Not used - Lin Diagnostics not required */
    product_id = 0x0040, 0x7001, 0xFF; /* Not used - Lin Diagnostics not required */
    response_error = UCIM_UCIM2_error_response_camper_st ;
    P2_min = 10 ms ;
    ST_min = 10 ms ;
    configurable_frames {
      CIM_SOFT_INPUT = 0x10 ;
      Slave_Error_Response_UCIM_UCIM2 = 0x1E ;
      SFB_STATUS = 0x01 ;
    }
    response_tolerance = 40 % ;
  }

}

Schedule_tables {
 LIN_D_Config_Sch_Tbl {
    BMS_D_FrP11 delay 20 ms ;
    SFB_STATUS delay 20 ms ;
  }
 LIN_D_Norm_Sch_Tbl_QM {
    BCM_D_FrP12 delay 20 ms ;
    BMS_D_FrP00 delay 20 ms ;
    BCM_D_FrP13 delay 20 ms ;
    BMS_D_FrP00 delay 20 ms ;
    BCM_D_FrP12 delay 20 ms ;
    BMS_D_FrP00 delay 20 ms ;
    BCM_D_FrP14 delay 20 ms ;
    BMS_D_FrP00 delay 20 ms ;
    BMS_D_FrP12 delay 20 ms ;
    BMS_D_FrP00 delay 20 ms ;
    BCM_D_FrP12 delay 20 ms ;
    BMS_D_FrP00 delay 20 ms ;
    BCM_D_FrP15 delay 20 ms ;
    BMS_D_FrP00 delay 20 ms ;
    BCM_D_FrP12 delay 20 ms ;
    BMS_D_FrP00 delay 20 ms ;
    BMS_D_FrP01 delay 20 ms ;
    BMS_D_FrP00 delay 20 ms ;
    BMS_D_FrP12 delay 20 ms ;
    BMS_D_FrP00 delay 20 ms ;
    BCM_D_FrP12 delay 20 ms ;
    BMS_D_FrP00 delay 20 ms ;
    BMS_D_FrP02 delay 20 ms ;
    BMS_D_FrP00 delay 20 ms ;
    BCM_D_FrP12 delay 20 ms ;
    BMS_D_FrP00 delay 20 ms ;
    BMS_D_FrP03 delay 20 ms ;
    BMS_D_FrP00 delay 20 ms ;
    BMS_D_FrP12 delay 20 ms ;
    BMS_D_FrP00 delay 20 ms ;
    BCM_D_FrP12 delay 20 ms ;
    BMS_D_FrP00 delay 20 ms ;
    BMS_D_FrP04 delay 20 ms ;
    BMS_D_FrP00 delay 20 ms ;
    BCM_D_FrP12 delay 20 ms ;
    BMS_D_FrP00 delay 20 ms ;
    BMS_D_FrP06 delay 20 ms ;
    BMS_D_FrP00 delay 20 ms ;
    BMS_D_FrP12 delay 20 ms ;
    BMS_D_FrP00 delay 20 ms ;
    BCM_D_FrP12 delay 20 ms ;
    BMS_D_FrP00 delay 20 ms ;
    BMS_D_FrP07 delay 20 ms ;
    BMS_D_FrP00 delay 20 ms ;
    BCM_D_FrP12 delay 20 ms ;
    BMS_D_FrP00 delay 20 ms ;
    BMS_D_FrP08 delay 20 ms ;
    BMS_D_FrP00 delay 20 ms ;
    BMS_D_FrP12 delay 20 ms ;
    BMS_D_FrP00 delay 20 ms ;
    BCM_D_FrP12 delay 20 ms ;
    BMS_D_FrP00 delay 20 ms ;
    BMS_D_FrP09 delay 20 ms ;
    BMS_D_FrP00 delay 20 ms ;
    BCM_D_FrP12 delay 20 ms ;
    BMS_D_FrP00 delay 20 ms ;
    BMS_D_FrP05 delay 20 ms ;
    BMS_D_FrP00 delay 20 ms ;
    BMS_D_FrP12 delay 20 ms ;
    BMS_D_FrP00 delay 20 ms ;
  }
 LIN_D_Sleep_Sch_Tbl_QM {
    BCM_D_FrP12 delay 20 ms ;
    BMS_D_FrP00 delay 20 ms ;
    BMS_D_FrP01 delay 20 ms ;
    BMS_D_FrP03 delay 20 ms ;
    BMS_D_FrP04 delay 20 ms ;
    BMS_D_FrP10 delay 20 ms ;
  }
 LIN_D_Norm_Sch_Tbl1_ASIL {
    BCM_D_FrP12 delay 20 ms ;
    BMS_D_FrP00 delay 20 ms ;
    BMS_D_FrASIL_001 delay 20 ms ;
    BMS_D_FrASIL_002 delay 20 ms ;
    BCM_D_FrP13 delay 20 ms ;
    BCM_D_FrP12 delay 20 ms ;
    BMS_D_FrP00 delay 20 ms ;
    BMS_D_FrASIL_001 delay 20 ms ;
    BMS_D_FrASIL_002 delay 20 ms ;
    BCM_D_FrP14 delay 20 ms ;
    BCM_D_FrP12 delay 20 ms ;
    BMS_D_FrP00 delay 20 ms ;
    BMS_D_FrASIL_001 delay 20 ms ;
    BMS_D_FrASIL_002 delay 20 ms ;
    BCM_D_FrP15 delay 20 ms ;
    BCM_D_FrP12 delay 20 ms ;
    BMS_D_FrP00 delay 20 ms ;
    BMS_D_FrASIL_001 delay 20 ms ;
    BMS_D_FrASIL_002 delay 20 ms ;
    BMS_D_FrP01 delay 20 ms ;
    BCM_D_FrP12 delay 20 ms ;
    BMS_D_FrP00 delay 20 ms ;
    BMS_D_FrASIL_001 delay 20 ms ;
    BMS_D_FrASIL_002 delay 20 ms ;
    BMS_D_FrP02 delay 20 ms ;
    BCM_D_FrP12 delay 20 ms ;
    BMS_D_FrP00 delay 20 ms ;
    BMS_D_FrASIL_001 delay 20 ms ;
    BMS_D_FrASIL_002 delay 20 ms ;
    BMS_D_FrP03 delay 20 ms ;
    BCM_D_FrP12 delay 20 ms ;
    BMS_D_FrP00 delay 20 ms ;
    BMS_D_FrASIL_001 delay 20 ms ;
    BMS_D_FrASIL_002 delay 20 ms ;
    BMS_D_FrP04 delay 20 ms ;
    BCM_D_FrP12 delay 20 ms ;
    BMS_D_FrP00 delay 20 ms ;
    BMS_D_FrASIL_001 delay 20 ms ;
    BMS_D_FrASIL_002 delay 20 ms ;
    BMS_D_FrP05 delay 20 ms ;
    BCM_D_FrP12 delay 20 ms ;
    BMS_D_FrP00 delay 20 ms ;
    BMS_D_FrASIL_001 delay 20 ms ;
    BMS_D_FrASIL_002 delay 20 ms ;
    BMS_D_FrP06 delay 20 ms ;
    BCM_D_FrP12 delay 20 ms ;
    BMS_D_FrP00 delay 20 ms ;
    BMS_D_FrASIL_001 delay 20 ms ;
    BMS_D_FrASIL_002 delay 20 ms ;
    BMS_D_FrP07 delay 20 ms ;
    BCM_D_FrP12 delay 20 ms ;
    BMS_D_FrP00 delay 20 ms ;
    BMS_D_FrASIL_001 delay 20 ms ;
    BMS_D_FrASIL_002 delay 20 ms ;
    BMS_D_FrP08 delay 20 ms ;
    BCM_D_FrP12 delay 20 ms ;
    BMS_D_FrP00 delay 20 ms ;
    BMS_D_FrASIL_001 delay 20 ms ;
    BMS_D_FrASIL_002 delay 20 ms ;
    BMS_D_FrP09 delay 20 ms ;
    BCM_D_FrP12 delay 20 ms ;
    BMS_D_FrP00 delay 20 ms ;
    BMS_D_FrASIL_001 delay 20 ms ;
    BMS_D_FrASIL_002 delay 20 ms ;
    BMS_D_FrP12 delay 20 ms ;
  }
 LIN_D_Norm_Sch_Tbl2_ASIL {
    BCM_D_FrP12 delay 20 ms ;
    BMS_D_FrP00 delay 20 ms ;
    BMS_D_FrASIL_001 delay 20 ms ;
    BMS_D_FrASIL_002 delay 20 ms ;
    BCM_D_FrP13 delay 20 ms ;
    BMS_D_FrP00 delay 20 ms ;
    BMS_D_FrASIL_001 delay 20 ms ;
    BMS_D_FrASIL_002 delay 20 ms ;
    BCM_D_FrP14 delay 20 ms ;
    BMS_D_FrP00 delay 20 ms ;
    BMS_D_FrASIL_001 delay 20 ms ;
    BMS_D_FrASIL_002 delay 20 ms ;
    BCM_D_FrP15 delay 20 ms ;
    BMS_D_FrP00 delay 20 ms ;
    BMS_D_FrASIL_001 delay 20 ms ;
    BMS_D_FrASIL_002 delay 20 ms ;
    BMS_D_FrP01 delay 20 ms ;
    BMS_D_FrP00 delay 20 ms ;
    BMS_D_FrASIL_001 delay 20 ms ;
    BMS_D_FrASIL_002 delay 20 ms ;
    BMS_D_FrP02 delay 20 ms ;
    BMS_D_FrASIL_001 delay 20 ms ;
    BMS_D_FrASIL_002 delay 20 ms ;
    BMS_D_FrP00 delay 20 ms ;
    BMS_D_FrP03 delay 20 ms ;
    BMS_D_FrP00 delay 20 ms ;
    BMS_D_FrASIL_001 delay 20 ms ;
    BMS_D_FrASIL_002 delay 20 ms ;
    BMS_D_FrP04 delay 20 ms ;
    BMS_D_FrP00 delay 20 ms ;
    BMS_D_FrASIL_001 delay 20 ms ;
    BMS_D_FrASIL_002 delay 20 ms ;
    BMS_D_FrP05 delay 20 ms ;
    BMS_D_FrP00 delay 20 ms ;
    BMS_D_FrASIL_001 delay 20 ms ;
    BMS_D_FrASIL_002 delay 20 ms ;
    BMS_D_FrP06 delay 20 ms ;
    BMS_D_FrP00 delay 20 ms ;
    BMS_D_FrASIL_001 delay 20 ms ;
    BMS_D_FrASIL_002 delay 20 ms ;
    BMS_D_FrP07 delay 20 ms ;
    BMS_D_FrASIL_001 delay 20 ms ;
    BMS_D_FrASIL_002 delay 20 ms ;
    BMS_D_FrP00 delay 20 ms ;
    BMS_D_FrP08 delay 20 ms ;
    BMS_D_FrP00 delay 20 ms ;
    BMS_D_FrASIL_001 delay 20 ms ;
    BMS_D_FrASIL_002 delay 20 ms ;
    BMS_D_FrP09 delay 20 ms ;
    BMS_D_FrASIL_001 delay 20 ms ;
    BMS_D_FrASIL_002 delay 20 ms ;
    BMS_D_FrP00 delay 20 ms ;
    BMS_D_FrP10 delay 20 ms ;
    BMS_D_FrP00 delay 20 ms ;
    BMS_D_FrASIL_001 delay 20 ms ;
    BMS_D_FrASIL_002 delay 20 ms ;
    BMS_D_FrP12 delay 20 ms ;
    BMS_D_FrP00 delay 20 ms ;
    BMS_D_FrASIL_001 delay 20 ms ;
    BMS_D_FrASIL_002 delay 20 ms ;
  }
 LIN_D_Sleep_Sch_Tbl_ASIL {
    BCM_D_FrP12 delay 20 ms ;
    BMS_D_FrP00 delay 20 ms ;
    BMS_D_FrASIL_001 delay 20 ms ;
    BMS_D_FrASIL_002 delay 20 ms ;
    BMS_D_FrP01 delay 20 ms ;
    BMS_D_FrASIL_001 delay 20 ms ;
    BMS_D_FrASIL_002 delay 20 ms ;
    BMS_D_FrP03 delay 20 ms ;
    BMS_D_FrP04 delay 20 ms ;
    BMS_D_FrASIL_001 delay 20 ms ;
    BMS_D_FrASIL_002 delay 20 ms ;
    BMS_D_FrP10 delay 20 ms ;
  }
 LIN_D_Dym_Ctrl_00 {
    BMS_D_FrP00 delay 20 ms ;
  }
 LIN_D_Dym_Ctrl_01 {
    BMS_D_FrP01 delay 20 ms ;
  }
 LIN_D_Dym_Ctrl_02 {
    BMS_D_FrP02 delay 20 ms ;
  }
 LIN_D_Dym_Ctrl_03 {
    BMS_D_FrP03 delay 20 ms ;
  }
 LIN_D_Dym_Ctrl_04 {
    BMS_D_FrP04 delay 20 ms ;
  }
 LIN_D_Dym_Ctrl_05 {
    BMS_D_FrP05 delay 20 ms ;
  }
 LIN_D_Dym_Ctrl_06 {
    BMS_D_FrP06 delay 20 ms ;
  }
 LIN_D_Dym_Ctrl_07 {
    BMS_D_FrP07 delay 20 ms ;
  }
 LIN_D_Dym_Ctrl_08 {
    BMS_D_FrP08 delay 20 ms ;
  }
 LIN_D_Dym_Ctrl_09 {
    BMS_D_FrP09 delay 20 ms ;
  }
 LIN_D_Dym_Ctrl_10 {
    BMS_D_FrP10 delay 20 ms ;
  }
 LIN_D_Dym_Ctrl_11 {
    BMS_D_FrP11 delay 20 ms ;
  }
 LIN_D_Dym_Ctrl_12 {
    BMS_D_FrP12 delay 20 ms ;
  }
 LIN_D_Dym_Ctrl_13 {
    BMS_D_FrASIL_001 delay 20 ms ;
  }
 LIN_D_Dym_Ctrl_14 {
    BMS_D_FrASIL_002 delay 20 ms ;
  }
 LIN_D_Dym_Ctrl_52 {
    BCM_D_FrP12 delay 20 ms ;
  }
 LIN_D_Dym_Ctrl_53 {
    BCM_D_FrP13 delay 20 ms ;
  }
 LIN_D_Dym_Ctrl_54 {
    BCM_D_FrP14 delay 20 ms ;
  }
 LIN_D_Dym_Ctrl_55 {
    BCM_D_FrP15 delay 20 ms ;
  }

LIN_D_Sleep_Sch_DualBMS_Tbl_QM {
    BCM_D_FrP12 delay 20 ms ;
    BCM_D_BMS2_FrP12 delay 20 ms ;
    BMS_D_FrP00 delay 20 ms ;
    BMS2_D_FrP00 delay 20 ms ;
    BMS_D_FrP01 delay 20 ms ;
    BMS2_D_FrP01 delay 20 ms ;
    BMS_D_FrP03 delay 20 ms ;
    BMS_D_FrP04 delay 20 ms ;
    BMS2_D_FrP03 delay 20 ms ;
    BMS2_D_FrP04 delay 20 ms ;
    BMS_D_FrP10 delay 20 ms ;
    BMS2_D_FrP10 delay 20 ms ;
  }

LIN_D_Norm_Sch_DualBMS_Tbl_QM {
    BCM_D_FrP12 delay 20 ms ;
    BCM_D_BMS2_FrP12 delay 20 ms ;
    BMS_D_FrP00 delay 20 ms ;
    BMS2_D_FrP00 delay 20 ms ;
    BCM_D_FrP13 delay 20 ms ;
    BCM_D_BMS2_FrP13 delay 20 ms ;
    BMS_D_FrP00 delay 20 ms ;
    BMS2_D_FrP00 delay 20 ms ;
    BCM_D_FrP12 delay 20 ms ;
    BCM_D_BMS2_FrP12 delay 20 ms ;
    BMS_D_FrP00 delay 20 ms ;
    BMS2_D_FrP00 delay 20 ms ;
    BCM_D_FrP14 delay 20 ms ;
    BCM_D_BMS2_FrP14 delay 20 ms ;
    BMS_D_FrP00 delay 20 ms ;
    BMS2_D_FrP00 delay 20 ms ;
    BMS_D_FrP12 delay 20 ms ;
    BMS2_D_FrP12 delay 20 ms ;
    BMS_D_FrP00 delay 20 ms ;
    BMS2_D_FrP00 delay 20 ms ;
    BCM_D_FrP12 delay 20 ms ;
    BCM_D_BMS2_FrP12 delay 20 ms ;
    BMS_D_FrP00 delay 20 ms ;
    BMS2_D_FrP00 delay 20 ms ;
    BCM_D_FrP15 delay 20 ms ;
    BCM_D_BMS2_FrP15 delay 20 ms ;
    BMS_D_FrP00 delay 20 ms ;
    BMS2_D_FrP00 delay 20 ms ;
    BCM_D_FrP12 delay 20 ms ;
    BCM_D_BMS2_FrP12 delay 20 ms ;
    BMS_D_FrP00 delay 20 ms ;
    BMS2_D_FrP00 delay 20 ms ;
    BMS_D_FrP01 delay 20 ms ;
    BMS2_D_FrP01 delay 20 ms ;
    BMS_D_FrP00 delay 20 ms ;
    BMS2_D_FrP00 delay 20 ms ;
    BMS_D_FrP12 delay 20 ms ;
    BMS2_D_FrP12 delay 20 ms ;
    BMS_D_FrP00 delay 20 ms ;
    BMS2_D_FrP00 delay 20 ms ;
    BCM_D_FrP12 delay 20 ms ;
    BCM_D_BMS2_FrP12 delay 20 ms ;
    BMS_D_FrP00 delay 20 ms ;
    BMS2_D_FrP00 delay 20 ms ;
    BMS_D_FrP02 delay 20 ms ;
    BMS2_D_FrP02 delay 20 ms ;
    BMS_D_FrP00 delay 20 ms ;
    BMS2_D_FrP00 delay 20 ms ;
    BCM_D_FrP12 delay 20 ms ;
    BCM_D_BMS2_FrP12 delay 20 ms ;
    BMS_D_FrP00 delay 20 ms ;
    BMS2_D_FrP00 delay 20 ms ;
    BMS_D_FrP03 delay 20 ms ;
    BMS2_D_FrP03 delay 20 ms ;
    BMS_D_FrP00 delay 20 ms ;
    BMS2_D_FrP00 delay 20 ms ;
    BMS_D_FrP12 delay 20 ms ;
    BMS2_D_FrP12 delay 20 ms ;
    BMS_D_FrP00 delay 20 ms ;
    BMS2_D_FrP00 delay 20 ms ;
    BCM_D_FrP12 delay 20 ms ;
    BCM_D_BMS2_FrP12 delay 20 ms ;
    BMS_D_FrP00 delay 20 ms ;
    BMS2_D_FrP00 delay 20 ms ;
    BMS_D_FrP04 delay 20 ms ;
    BMS2_D_FrP04 delay 20 ms ;
    BMS_D_FrP00 delay 20 ms ;
    BMS2_D_FrP00 delay 20 ms ;
    BCM_D_FrP12 delay 20 ms ;
    BCM_D_BMS2_FrP12 delay 20 ms ;
    BMS_D_FrP00 delay 20 ms ;
    BMS2_D_FrP00 delay 20 ms ;
    BMS_D_FrP06 delay 20 ms ;
    BMS2_D_FrP06 delay 20 ms ;
    BMS_D_FrP00 delay 20 ms ;
    BMS2_D_FrP00 delay 20 ms ;
    BMS_D_FrP12 delay 20 ms ;
    BMS2_D_FrP12 delay 20 ms ;
    BMS_D_FrP00 delay 20 ms ;
    BMS2_D_FrP00 delay 20 ms ;
    BCM_D_FrP12 delay 20 ms ;
    BCM_D_BMS2_FrP12 delay 20 ms ;
    BMS_D_FrP00 delay 20 ms ;
    BMS2_D_FrP00 delay 20 ms ;
    BMS_D_FrP07 delay 20 ms ;
    BMS2_D_FrP07 delay 20 ms ;
    BMS_D_FrP00 delay 20 ms ;
    BMS2_D_FrP00 delay 20 ms ;
    BCM_D_FrP12 delay 20 ms ;
    BCM_D_BMS2_FrP12 delay 20 ms ;
    BMS_D_FrP00 delay 20 ms ;
    BMS2_D_FrP00 delay 20 ms ;
    BMS_D_FrP08 delay 20 ms ;
    BMS2_D_FrP08 delay 20 ms ;
    BMS_D_FrP00 delay 20 ms ;
    BMS2_D_FrP00 delay 20 ms ;
    BMS_D_FrP12 delay 20 ms ;
    BMS2_D_FrP12 delay 20 ms ;
    BMS_D_FrP00 delay 20 ms ;
    BMS2_D_FrP00 delay 20 ms ;
    BCM_D_FrP12 delay 20 ms ;
    BCM_D_FrP12 delay 20 ms ;
    BMS_D_FrP00 delay 20 ms ;
    BMS2_D_FrP00 delay 20 ms ;
    BMS_D_FrP09 delay 20 ms ;
    BMS2_D_FrP09 delay 20 ms ;
    BMS_D_FrP00 delay 20 ms ;
    BMS2_D_FrP00 delay 20 ms ;
    BCM_D_FrP12 delay 20 ms ;
    BCM_D_FrP12 delay 20 ms ;
    BMS_D_FrP00 delay 20 ms ;
    BMS2_D_FrP00 delay 20 ms ;
    BMS_D_FrP05 delay 20 ms ;
    BMS2_D_FrP05 delay 20 ms ;
    BMS_D_FrP00 delay 20 ms ;
    BMS2_D_FrP00 delay 20 ms ;
    BMS_D_FrP12 delay 20 ms ;
    BMS2_D_FrP12 delay 20 ms ;
    BMS_D_FrP00 delay 20 ms ;
    BMS2_D_FrP00 delay 20 ms ;
  }

LIN_D_Norm_Sch_DualBMS_Tbl_ASIL {
    BCM_D_FrP12 delay 20 ms ;
  BCM_D_BMS2_FrP12 delay 20 ms ;
    BMS_D_FrP00 delay 20 ms ;
  BMS2_D_FrP00 delay 20 ms ;
    BMS_D_FrASIL_001 delay 20 ms ;
    BMS_D_FrASIL_002 delay 20 ms ;
    BCM_D_FrP13 delay 20 ms ;
  BCM_D_BMS2_FrP13 delay 20 ms ;
    BCM_D_FrP12 delay 20 ms ;
    BMS_D_FrASIL_001 delay 20 ms ;
    BMS_D_FrASIL_002 delay 20 ms ;
  BCM_D_BMS2_FrP12 delay 20 ms ;
    BMS_D_FrP00 delay 20 ms ;
  BMS2_D_FrP00 delay 20 ms ;
    BMS_D_FrASIL_001 delay 20 ms ;
    BMS_D_FrASIL_002 delay 20 ms ;
    BCM_D_FrP14 delay 20 ms ;
  BCM_D_BMS2_FrP14 delay 20 ms ;
    BCM_D_FrP12 delay 20 ms ;
    BMS_D_FrASIL_001 delay 20 ms ;
    BMS_D_FrASIL_002 delay 20 ms ;
  BCM_D_BMS2_FrP12 delay 20 ms ;
    BMS_D_FrP00 delay 20 ms ;
  BMS2_D_FrP00 delay 20 ms ;
    BMS_D_FrASIL_001 delay 20 ms ;
    BMS_D_FrASIL_002 delay 20 ms ;
    BCM_D_FrP15 delay 20 ms ;
  BCM_D_BMS2_FrP15 delay 20 ms ;
    BCM_D_FrP12 delay 20 ms ;
    BMS_D_FrASIL_001 delay 20 ms ;
    BMS_D_FrASIL_002 delay 20 ms ;
  BCM_D_BMS2_FrP12 delay 20 ms ;
    BMS_D_FrP00 delay 20 ms ;
  BMS2_D_FrP00 delay 20 ms ;
    BMS_D_FrASIL_001 delay 20 ms ;
    BMS_D_FrASIL_002 delay 20 ms ;
    BMS_D_FrP01 delay 20 ms ;
  BMS2_D_FrP01 delay 20 ms ;
    BCM_D_FrP12 delay 20 ms ;
    BMS_D_FrASIL_001 delay 20 ms ;
    BMS_D_FrASIL_002 delay 20 ms ;
  BCM_D_BMS2_FrP12 delay 20 ms ;
    BMS_D_FrP00 delay 20 ms ;
  BMS2_D_FrP00 delay 20 ms ;
    BMS_D_FrASIL_001 delay 20 ms ;
    BMS_D_FrASIL_002 delay 20 ms ;
    BMS_D_FrP02 delay 20 ms ;
  BMS2_D_FrP02 delay 20 ms ;
    BCM_D_FrP12 delay 20 ms ;
    BMS_D_FrASIL_001 delay 20 ms ;
    BMS_D_FrASIL_002 delay 20 ms ;
  BCM_D_BMS2_FrP12 delay 20 ms ;
    BMS_D_FrP00 delay 20 ms ;
  BMS2_D_FrP00 delay 20 ms ;
    BMS_D_FrASIL_001 delay 20 ms ;
    BMS_D_FrASIL_002 delay 20 ms ;
    BMS_D_FrP03 delay 20 ms ;
  BMS2_D_FrP03 delay 20 ms ;
    BCM_D_FrP12 delay 20 ms ;
    BMS_D_FrASIL_001 delay 20 ms ;
    BMS_D_FrASIL_002 delay 20 ms ;
  BCM_D_BMS2_FrP12 delay 20 ms ;
    BMS_D_FrP00 delay 20 ms ;
  BMS2_D_FrP00 delay 20 ms ;
    BMS_D_FrASIL_001 delay 20 ms ;
    BMS_D_FrASIL_002 delay 20 ms ;
    BMS_D_FrP04 delay 20 ms ;
  BMS2_D_FrP04 delay 20 ms ;
    BCM_D_FrP12 delay 20 ms ;
    BMS_D_FrASIL_001 delay 20 ms ;
    BMS_D_FrASIL_002 delay 20 ms ;
  BCM_D_BMS2_FrP12 delay 20 ms ;
    BMS_D_FrP00 delay 20 ms ;
  BMS2_D_FrP00 delay 20 ms ;
    BMS_D_FrASIL_001 delay 20 ms ;
    BMS_D_FrASIL_002 delay 20 ms ;
    BMS_D_FrP05 delay 20 ms ;
  BMS2_D_FrP05 delay 20 ms ;
    BCM_D_FrP12 delay 20 ms ;
    BMS_D_FrASIL_001 delay 20 ms ;
    BMS_D_FrASIL_002 delay 20 ms ;
  BCM_D_BMS2_FrP12 delay 20 ms ;
    BMS_D_FrP00 delay 20 ms ;
  BMS2_D_FrP00 delay 20 ms ;
    BMS_D_FrASIL_001 delay 20 ms ;
    BMS_D_FrASIL_002 delay 20 ms ;
    BMS_D_FrP06 delay 20 ms ;
  BMS2_D_FrP06 delay 20 ms ;
    BCM_D_FrP12 delay 20 ms ;
    BMS_D_FrASIL_001 delay 20 ms ;
    BMS_D_FrASIL_002 delay 20 ms ;
  BCM_D_BMS2_FrP12 delay 20 ms ;
    BMS_D_FrP00 delay 20 ms ;
  BMS2_D_FrP00 delay 20 ms ;
    BMS_D_FrASIL_001 delay 20 ms ;
    BMS_D_FrASIL_002 delay 20 ms ;
    BMS_D_FrP07 delay 20 ms ;
  BMS2_D_FrP07 delay 20 ms ;
    BCM_D_FrP12 delay 20 ms ;
    BMS_D_FrASIL_001 delay 20 ms ;
    BMS_D_FrASIL_002 delay 20 ms ;
  BCM_D_BMS2_FrP12 delay 20 ms ;
    BMS_D_FrP00 delay 20 ms ;
  BMS2_D_FrP00 delay 20 ms ;
    BMS_D_FrASIL_001 delay 20 ms ;
    BMS_D_FrASIL_002 delay 20 ms ;
    BMS_D_FrP08 delay 20 ms ;
  BMS2_D_FrP08 delay 20 ms ;
    BCM_D_FrP12 delay 20 ms ;
    BMS_D_FrASIL_001 delay 20 ms ;
    BMS_D_FrASIL_002 delay 20 ms ;
  BCM_D_BMS2_FrP12 delay 20 ms ;
    BMS_D_FrP00 delay 20 ms ;
  BMS2_D_FrP00 delay 20 ms ;
    BMS_D_FrASIL_001 delay 20 ms ;
    BMS_D_FrASIL_002 delay 20 ms ;
    BMS_D_FrP09 delay 20 ms ;
  BMS2_D_FrP09 delay 20 ms ;
    BCM_D_FrP12 delay 20 ms ;
    BMS_D_FrASIL_001 delay 20 ms ;
    BMS_D_FrASIL_002 delay 20 ms ;
  BCM_D_BMS2_FrP12 delay 20 ms ;
    BMS_D_FrP00 delay 20 ms ;
  BMS2_D_FrP00 delay 20 ms ;
    BMS_D_FrASIL_001 delay 20 ms ;
    BMS_D_FrASIL_002 delay 20 ms ;
    BMS_D_FrP12 delay 20 ms ;
  BMS2_D_FrP12 delay 20 ms ;
  }

LIN_D_Sleep_Sch_DualBMS_Tbl_ASIL {
    BCM_D_FrP12 delay 20 ms ;
    BCM_D_BMS2_FrP12 delay 20 ms ;
    BMS_D_FrP00 delay 20 ms ;
    BMS2_D_FrP00 delay 20 ms ;
    BMS_D_FrASIL_001 delay 20 ms ;
    BMS_D_FrASIL_002 delay 20 ms ;
    BMS_D_FrP01 delay 20 ms ;
    BMS2_D_FrP01 delay 20 ms ;
    BMS_D_FrASIL_001 delay 20 ms ;
    BMS_D_FrASIL_002 delay 20 ms ;
    BMS_D_FrP03 delay 20 ms ;
    BMS_D_FrP04 delay 20 ms ;
    BMS2_D_FrP03 delay 20 ms ;
    BMS2_D_FrP04 delay 20 ms ;
    BMS_D_FrASIL_001 delay 20 ms ;
    BMS_D_FrASIL_002 delay 20 ms ;
    BMS_D_FrP10 delay 20 ms ;
    BMS2_D_FrP10 delay 20 ms ;
  }

}

Signal_encoding_types {
  LINStatus_ET {
    physical_value, 0, 255, 1, 0, "LIN Status" ;
  }
  BSBattCurrentCoding {
    physical_value, 0, 182272, 0.00390625, -512, "A" ;
  }
  BSBatt_Current_ASIL_Encoding {
    physical_value, 0, 182272, 0.00390625, -512, "A" ;
    logical_value, 16777215, "Invalid" ;
  }
  BSBattQCapAhLINCoding {
    physical_value, 0, 100, 1, 0, "Ah" ;
  }
  BSBattSOHSULStatusCoding {
    logical_value, 0, "Learning / relearning SUL" ;
    logical_value, 1, "SUL learning complete" ;
    logical_value, 2, "Reserved" ;
    logical_value, 3, "Reserved" ;
  }
  BSBattSOHLAMStatusCoding {
    logical_value, 0, "No detection or unknown" ;
    logical_value, 1, "Detected in the last 60 days" ;
    logical_value, 2, "Detected in the last 90 days" ;
    logical_value, 3, "Detected in more than 90 days" ;
  }
  BSBlindChargeFlagCoding {
    logical_value, 0, "No Fault" ;
    logical_value, 1, "BSBlindCharge was detected" ;
  }
  BSBattQDchQDCnCoding {
    physical_value, 0, 12800, 0.015625, 0, "Counts";
  }
  BSBattQDeltaRideAhLINCoding {
    physical_value, 0, 25600, 0.0078125, -100, "Ah" ;
  }
  BSBattSOCCoding {
    physical_value, 0, 100, 1, 0, "%" ;
  }
  BSBattSOCStatusCoding {
    logical_value, 1, "10% < BSBattSOC Accuracy <= 15%" ;
    logical_value, 2, "BSBattSOC Accuracy <= 10%" ;
    logical_value, 3, "BSBattSOC Accuracy > 15% or Status Unknown" ;
  }
  BSBattTempCoding {
    physical_value, 0, 140, 1, -40, "Degree Celsius" ;
  }
  BSBattTimeInServiceCoding {
    physical_value, 0, 4095, 1, 0, "Days" ;
  }
  BSBattTSOFQDCoding {
    physical_value, 0, 255, 1, 0, "Days" ;
  }
  BSBattTSOFWCCCoding {
    physical_value, 0, 255, 8, 0, "Seconds" ;
  }
  BSBattVoltageCoding {
    physical_value, 0, 19456, 0.0009765625, 0, "V" ;
  }
  BSBatt_Voltage_ASIL_Encoding {
    physical_value, 0, 19455, 0.0009765625, 0, "V" ;
    logical_value, 32767, "Invalid" ;
  }
  BSBattVSOFCCCCoding {
    physical_value, 0, 255, 0.0625, 0, "V" ;
  }
  BSBatt_I_QDCoding {
    physical_value, 0, 511, 1, 0, "mA" ;
  }
  BSBatt_Ri_ASIL_Encoding {
    physical_value, 0, 4094, 0.0625, 0, "mOhm" ;
    physical_value, 4095, 4095, 1, 0, "Invalid" ;
    logical_value, 4095, "Invalid" ;
  }
  BSBatt_Ri_Error_ASIL_Encoding {
    physical_value, 0, 13, 1, 2, "%" ;
    physical_value, 14, 14, 1, 0, "Inaccurate (>15%)" ;
    physical_value, 15, 15, 1, 0, "Invalid" ;
    logical_value, 14, "Inaccurate (>15%)" ;
    logical_value, 15, "Invalid" ;
  }
  BSBatt_SOF_ASIL_Encoding {
    physical_value, 0, 254, 0.0625, 0, "V" ;
    physical_value, 255, 255, 1, 0, "Invalid" ;
    logical_value, 255, "Invalid" ;
  }
  BSBatt_SOF_Error_ASIL_Encoding {
    physical_value, 0, 12, 50, 50, "mV" ;
    physical_value, 14, 14, 1, 0, "Inaccurate" ;
    physical_value, 15, 15, 1, 0, "Invalid" ;
    physical_value, 13, 13, 1, 0, "Safe prediction" ;
    logical_value, 13, "Safe prediction" ;
    logical_value, 14, "Inaccurate" ;
    logical_value, 15, "Invalid" ;
  }
  BSDiagResetCoding {
    logical_value, 0, "No reset" ;
    logical_value, 1, "Reset" ;
  }
  BSFaultLINCoding {
    logical_value, 0, "No Fault" ;
    logical_value, 1, "HW Fault" ;
  }
  BSModeCoding {
    logical_value, 0, "Transport Mode not active" ;
    logical_value, 1, "Transport Mode active" ;
  }
  BSPowerOnJustOccuredCoding {
    logical_value, 0, "No PowerOn Occured" ;
    logical_value, 1, "PowerOn Occured" ;
  }
  BSStratificationCoding {
    logical_value, 0, "No Fault" ;
    logical_value, 1, "Fault" ;
  }
  BSConsistencyFaultCoding {
    logical_value, 0, "No fault" ;
    logical_value, 1, "BSConsistencyFault was detected" ;
  }
  BSShortedCellCoding {
    logical_value, 0, "No fault" ;
    logical_value, 1, "Shorted cell detected" ;
  }
  BSDiagResetFlagCoding {
    logical_value, 0, "No issue" ;
    logical_value, 1, "BSDiagReset was detected" ;
  }
  BSFaultFlagCoding {
    logical_value, 0, "No issue" ;
    logical_value, 1, "BSFault was detected" ;
  }
  BatteryParametersFlagCoding {
    logical_value, 0, "No issue" ;
    logical_value, 1, "New Battery Parameters" ;
  }
  PORFlagCoding {
    logical_value, 0, "No issue" ;
    logical_value, 1, "POR was detected" ;
  }
  AhFlagCoding {
    logical_value, 0, "No issue" ;
    logical_value, 1, "SOC integrator accuracy" ;
  }
  TransportFlagCoding {
    logical_value, 0, "No issue" ;
    logical_value, 1, "Transport mode was detected" ;
  }
  FullChrgDetectedCoding {
    logical_value, 0, "Not fully charged" ;
    logical_value, 1, "Fully charged" ;
  }
  BSBattSOCRecalUsedCoding {
    logical_value, 0, "Sleep Mode OCV" ;
    logical_value, 1, "Full Charge Detection" ;
    logical_value, 2, "Active Mode" ;
    logical_value, 3, "No Recal - power reset" ;
  }
  CnCoding {
    physical_value, 0, 64000, 0.015625, 0, "Counts" ;
  }
  BSBattRiCoding {
    physical_value, 0, 511, 0.0625, 0, "mOhm" ;
  }
  BSBattRiStatusCoding {
    logical_value, 1, "No learning" ;
    logical_value, 2, "Learned in current active phase" ;
    logical_value, 3, "Not learned in current active phase" ;
  }
  BSBattCurrentECOSCoding {
    physical_value, 0, 65535, 0.0625, -2048, "A" ;
  }
  BSBattVoltageECOSCoding {
    physical_value, 0, 4864, 0.00390625, 0, "V" ;
  }
  BSCrankVoltageCoding {
    physical_value, 0, 4095, 0.00390625, 0, "V" ;
  }
  BSCrankCurrentCoding {
    physical_value, 0, 20800, 0.0625, -1300, "A" ;
  }
  BSBatt_Ah_QDCoding {
    physical_value, 0, 7680, 0.0078125, 0, "Ah" ;
  }
  BSBatt_Ah_QD_TBCoding {
    logical_value, 0, "if previous value = 1 then updated" ;
    logical_value, 1, "if previous value = 0 then updated" ;
  }
  BSBatt_Ah_QD_TimerCoding {
    physical_value, 0, 65535, 1, 0, "Minutes" ;
  }
  BSBatt_Batt_Off_ASIL_Encoding {
    logical_value, 0, "Battery connected" ;
    logical_value, 1, "Battery disconnection detected" ;
  }
  BSBattOCVCoding {
    physical_value, 0, 127, 0.015625, 11.1875, "V" ;
  }
  BSBattKoLCurrentCoding {
    physical_value, 0, 32767, 0.0009765625, -31.9990234375, "A" ;
  }
  BSWaterLossCoding {
    physical_value, 0, 1023, 2, 0, "grams" ;
  }
  BSGassingRateCoding {
    physical_value, 0, 4095, 0.0078125, 0, "grams/hour" ;
  }
  BSAutoDiagResetCounterCoding {
    physical_value, 0, 31, 1, 0, "Counts" ;
  }
  BSBattSOF_V_WCCCoding {
    physical_value, 0, 255, 0.0625, 0, "V" ;
  }
  BSBattSOF_I_WCCCoding {
    physical_value, 0, 2047, 1, 0, "A" ;
  }
  IgnKeyPositionCoding {
    logical_value, 0, "Off" ;
    logical_value, 1, "Accessory" ;
    logical_value, 2, "Ignition On or engine running" ;
    logical_value, 3, "Cranking" ;
  }
  SleepModeCoding {
    logical_value, 0, "Deactivate Transport Mode" ;
    logical_value, 1, "Activate Transport Mode" ;
  }
  AutoStopCurrentEstCoding {
    physical_value, 0, 127, 2, 0, "A" ;
  }
  BatterySizeCoding {
    logical_value, 0, "Undefined" ;
    logical_value, 1, "T4" ;
    logical_value, 2, "T5" ;
    logical_value, 3, "T6" ;
    logical_value, 4, "T7" ;
    logical_value, 5, "T8" ;
    logical_value, 6, "96R" ;
    logical_value, 7, "67R" ;
    logical_value, 8, "Reserved" ;
    logical_value, 9, "Reserved" ;
    logical_value, 10, "H4" ;
    logical_value, 11, "H5" ;
    logical_value, 12, "H6" ;
    logical_value, 13, "H7" ;
    logical_value, 14, "H8" ;
    logical_value, 15, "Reserved" ;
    logical_value, 16, "Reserved" ;
    logical_value, 17, "Reserved" ;
    logical_value, 18, "Reserved" ;
    logical_value, 19, "Reserved" ;
    logical_value, 20, "Reserved" ;
    logical_value, 21, "Reserved" ;
    logical_value, 22, "Reserved" ;
    logical_value, 23, "Reserved" ;
    logical_value, 24, "Reserved" ;
    logical_value, 25, "Reserved" ;
    logical_value, 26, "Reserved" ;
    logical_value, 27, "Reserved" ;
    logical_value, 28, "Reserved" ;
    logical_value, 29, "Reserved" ;
    logical_value, 30, "Reserved" ;
    logical_value, 31, "Reserved" ;
  }
  BatteryDesignCoding {
    logical_value, 0, "Undefined" ;
    logical_value, 1, "Flooded" ;
    logical_value, 2, "Improved Flooded" ;
    logical_value, 3, "AGM" ;
  }
  BattNormAcidCapacityCoding {
    physical_value, 0, 665, 0.0009765625, 0.5, "100%/V" ;
  }
  BatteryCCACoding {
    physical_value, 0, 700, 2, 100, "A" ;
  }
  BatteryCapacityCoding {
    physical_value, 0, 235, 1, 20, "Ah" ;
  }
  Ri_25CCoding {
    physical_value, 0, 127, 0.125, 0, "mOhm" ;
  }
  StarterResistanceCoding {
    physical_value, 0, 255, 0.125, 0, "mOhm" ;
  }
  CurrentLoadDurationCoding {
    physical_value, 0, 1023, 0.0625, 0, "sec" ;
  }
  CurrentLoadMagnitudeCoding {
    physical_value, 0, 1023, 1, 0, "A" ;
  }
  BatteryUC0maxCoding {
    physical_value, 0, 920, 0.0009765625, 12.600585938, "V" ;
  }
  POI_SOC_CalCoding {
    logical_value, 0, "no threshold" ;
    logical_value, 1, "threshold1" ;
    logical_value, 2, "threshold2" ;
    logical_value, 3, "threshold3" ;
  }
  BatteryBCMTableNumberCoding {
    physical_value, 0, 511, 1, 0, "N/A" ;
  }
  ICrankCoding {
    physical_value, 0, 255, 8, 0, "A" ;
  }

  LINStatus_ET_BMS2 {
    physical_value, 0, 255, 1, 0, "LIN Status BMS2" ;
  }
  LINStatus_ET_UCIM_UCIM2_Coding {
    physical_value, 0, 255, 1, 0, "LIN Status UCIM_UCIM2" ;
  }
  BSBatt2CurrentCoding {
    physical_value, 0, 182272, 0.00390625, -512, "A" ;
  }
  BSBatt2QCapAhLINCoding {
    physical_value, 0, 100, 1, 0, "Ah" ;
  }
  BSBatt2SOHSULStatusCoding {
    logical_value, 0, "Learning / relearning SUL" ;
    logical_value, 1, "SUL learning complete" ;
    logical_value, 2, "Reserved" ;
    logical_value, 3, "Reserved" ;
  }
  BSBatt2SOHLAMStatusCoding {
    logical_value, 0, "No detection or unknown" ;
    logical_value, 1, "Detected in the last 60 days" ;
    logical_value, 2, "Detected in the last 90 days" ;
    logical_value, 3, "Detected in more than 90 days" ;
  }
  BS2BlindChargeFlagCoding {
    logical_value, 0, "No Fault" ;
    logical_value, 1, "BS2BlindCharge was detected" ;
  }
  BSBatt2QDchQDCnCoding {
    physical_value, 0, 12800, 0.015625, 0, "Counts" ;
  }
  BSBatt2QDeltaRideAhLINCoding {
    physical_value, 0, 25600, 0.0078125, -100, "Ah" ;
  }
  BSBatt2SOCCoding {
    physical_value, 0, 100, 1, 0, "%" ;
  }
  BSBatt2SOCStatusCoding {
    logical_value, 1, "10% < BSBatt2SOC Accuracy <= 15%" ;
    logical_value, 2, "BSBatt2SOC Accuracy <= 10%" ;
    logical_value, 3, "BSBatt2SOC Accuracy > 15% or Status Unknown" ;
  }
  BSBatt2TempCoding {
    physical_value, 0, 140, 1, -40, "Degree Celsius" ;
  }
  BSBatt2TimeInServiceCoding {
    physical_value, 0, 4095, 1, 0, "Days" ;
  }
  BSBatt2TSOFQDCoding {
    physical_value, 0, 255, 1, 0, "Days" ;
  }
  BSBatt2TSOFWCCCoding {
    physical_value, 0, 255, 8, 0, "Seconds" ;
  }
  BSBatt2VoltageCoding {
    physical_value, 0, 19456, 0.0009765625, 0, "V" ;
  }
  BSBatt2VSOFCCCCoding {
    physical_value, 0, 255, 0.0625, 0, "V" ;
  }
  BSBatt2_I_QDCoding {
    physical_value, 0, 511, 1, 0, "mA" ;
  }
  BSDiagReset_BMS2_Coding {
    logical_value, 0, "No reset" ;
    logical_value, 1, "Reset" ;
  }
  BS2FaultLINCoding {
    logical_value, 0, "No Fault" ;
    logical_value, 1, "HW Fault" ;
  }
  BS2ModeCoding {
    logical_value, 0, "Transport Mode not active" ;
    logical_value, 1, "Transport Mode active" ;
  }
  BS2PowerOnJustOccuredCoding {
    logical_value, 0, "No PowerOn Occured" ;
    logical_value, 1, "PowerOn Occured" ;
  }
  BS2StratificationCoding {
    logical_value, 0, "No Fault" ;
    logical_value, 1, "Fault" ;
  }
  BS2ConsistencyFaultCoding {
    logical_value, 0, "No fault" ;
    logical_value, 1, "BS2ConsistencyFault was detected" ;
  }
  BS2ShortedCellCoding {
    logical_value, 0, "No fault" ;
    logical_value, 1, "Shorted cell detected" ;
  }
  BS2DiagResetFlagCoding {
    logical_value, 0, "No issue" ;
    logical_value, 1, "BS2DiagReset was detected" ;
  }
  BS2FaultFlagCoding {
    logical_value, 0, "No issue" ;
    logical_value, 1, "BS2Fault was detected" ;
  }
  Battery2ParametersFlagCoding {
    logical_value, 0, "No issue" ;
    logical_value, 1, "New battery2 Parameters" ;
  }
  PORFlag_BMS2_Coding {
    logical_value, 0, "No issue" ;
    logical_value, 1, "POR was detected" ;
  }
  AhFlag_BMS2_Coding {
    logical_value, 0, "No issue" ;
    logical_value, 1, "SOC integrator accuracy" ;
  }
  TransportFlag_BMS2_Coding {
    logical_value, 0, "No issue" ;
    logical_value, 1, "Transport mode was detected" ;
  }
  FullChrgDetected_BMS2_Coding {
    logical_value, 0, "Not fully charged" ;
    logical_value, 1, "Fully charged" ;
  }
  BSBatt2SOCRecalUsedCoding {
    logical_value, 0, "Sleep Mode OCV" ;
    logical_value, 1, "Full Charge Detection" ;
    logical_value, 2, "Active Mode" ;
    logical_value, 3, "No Recal - power reset" ;
  }
  Cn_BMS2_Coding {
    physical_value, 0, 64000, 0.015625, 0, "Counts" ;
  }
  BSBatt2RiCoding {
    physical_value, 0, 511, 0.0625, 0, "mOhm" ;
  }
  BSBatt2RiStatusCoding {
    logical_value, 1, "No learning" ;
    logical_value, 2, "Learned in current active phase" ;
    logical_value, 3, "Not learned in current active phase" ;
  }
  BSBatt2CurrentECOSCoding {
    physical_value, 0, 65535, 0.0625, -2048, "A" ;
  }
  BSBatt2VoltageECOSCoding {
    physical_value, 0, 4864, 0.00390625, 0, "V" ;
  }
  BS2CrankVoltageCoding {
    physical_value, 0, 4095, 0.00390625, 0, "V" ;
  }
  BS2CrankCurrentCoding {
    physical_value, 0, 20800, 0.0625, -1300, "A" ;
  }
  BSBatt2_Ah_QDCoding {
    physical_value, 0, 7680, 0.0078125, 0, "Ah" ;
  }
  BSBatt2_Ah_QD_TBCoding {
    logical_value, 0, "if previous value = 1 then updated" ;
    logical_value, 1, "if previous value = 0 then updated" ;
  }
  BSBatt2_Ah_QD_TimerCoding {
    physical_value, 0, 65535, 1, 0, "Minutes" ;
  }
  BSBatt2_Batt_Off_ASIL_Encoding {
    logical_value, 0, "battery2 connected" ;
    logical_value, 1, "battery2 disconnection detected" ;
  }
  BSBatt2OCVCoding {
    physical_value, 0, 127, 0.015625, 11.1875, "V" ;
  }
  BSBatt2KoLCurrentCoding {
    physical_value, 0, 32767, 0.0009765625, -31.9990234375, "A" ;
  }
  BS2WaterLossCoding {
    physical_value, 0, 1023, 2, 0, "grams" ;
  }
  BS2GassingRateCoding {
    physical_value, 0, 4095, 0.0078125, 0, "grams/hour" ;
  }
  BS2AutoDiagResetCounterCoding {
    physical_value, 0, 31, 1, 0, "Counts" ;
  }
  BSBatt2SOF_V_WCCCoding {
    physical_value, 0, 255, 0.0625, 0, "V" ;
  }
  BSBatt2SOF_I_WCCCoding {
    physical_value, 0, 2047, 1, 0, "A" ;
  }
  IgnKeyPosition_BMS2_Coding {
    logical_value, 0, "Off" ;
    logical_value, 1, "Accessory" ;
    logical_value, 2, "Ignition On or engine running" ;
    logical_value, 3, "Cranking" ;
  }
  SleepMode_BMS2_Coding {
    logical_value, 0, "Deactivate Transport Mode" ;
    logical_value, 1, "Activate Transport Mode" ;
  }
  AutoStopCurrentEst_BMS2_Coding {
    physical_value, 0, 127, 2, 0, "A" ;
  }
  Battery2SizeCoding {
    logical_value, 0, "Undefined" ;
    logical_value, 1, "T4" ;
    logical_value, 2, "T5" ;
    logical_value, 3, "T6" ;
    logical_value, 4, "T7" ;
    logical_value, 5, "T8" ;
    logical_value, 6, "96R" ;
    logical_value, 7, "67R" ;
    logical_value, 8, "Reserved" ;
    logical_value, 9, "Reserved" ;
    logical_value, 10, "H4" ;
    logical_value, 11, "H5" ;
    logical_value, 12, "H6" ;
    logical_value, 13, "H7" ;
    logical_value, 14, "H8" ;
    logical_value, 15, "Reserved" ;
    logical_value, 16, "Reserved" ;
    logical_value, 17, "Reserved" ;
    logical_value, 18, "Reserved" ;
    logical_value, 19, "Reserved" ;
    logical_value, 20, "Reserved" ;
    logical_value, 21, "Reserved" ;
    logical_value, 22, "Reserved" ;
    logical_value, 23, "Reserved" ;
    logical_value, 24, "Reserved" ;
    logical_value, 25, "Reserved" ;
    logical_value, 26, "Reserved" ;
    logical_value, 27, "Reserved" ;
    logical_value, 28, "Reserved" ;
    logical_value, 29, "Reserved" ;
    logical_value, 30, "Reserved" ;
    logical_value, 31, "Reserved" ;
  }
  Battery2DesignCoding {
    logical_value, 0, "Undefined" ;
    logical_value, 1, "Flooded" ;
    logical_value, 2, "Improved Flooded" ;
    logical_value, 3, "AGM" ;
  }
  Batt2NormAcidCapacityCoding {
    physical_value, 0, 665, 0.0009765625, 0.5, "100%/V" ;
  }
  Battery2CCACoding {
    physical_value, 0, 700, 2, 100, "A" ;
  }
  Battery2CapacityCoding {
    physical_value, 0, 235, 1, 20, "Ah" ;
  }
  Ri_25C_Battery2_Coding {
    physical_value, 0, 127, 0.125, 0, "mOhm" ;
  }
  StarterResistance_BMS2_Coding {
    physical_value, 0, 255, 0.125, 0, "mOhm" ;
  }
  CurrentLoadDuration_BMS2_Coding {
    physical_value, 0, 1023, 0.0625, 0, "sec" ;
  }
  CurrentLoadMagnitude_BMS2_Coding {
    physical_value, 0, 1023, 1, 0, "A" ;
  }
  Battery2UC0maxCoding {
    physical_value, 0, 920, 0.0009765625, 12.600585938, "V" ;
  }
  POI_SOC_Cal_BMS2_Coding {
    logical_value, 0, "no threshold" ;
    logical_value, 1, "threshold1" ;
    logical_value, 2, "threshold2" ;
    logical_value, 3, "threshold3" ;
  }
  Battery2BCMTableNumberCoding {
    physical_value, 0, 511, 1, 0, "N/A" ;
  }
  ICrank_BMS2_Coding {
    physical_value, 0, 255, 8, 0, "A" ;
  }

   SoftButtonCoding {
      logical_value, 0, "Default";
      logical_value, 1, "Output 0V";
    logical_value, 2, "Output 12V";
   }

   FuseStateCoding {
      logical_value, 0, "Output Off";
      logical_value, 1, "Output On";
    logical_value, 2, "Output Blown";
   }

   InputStateCoding {
      logical_value, 0, "Input Low";
      logical_value, 1, "Input High";
   }

   RelayStateCoding {
      logical_value, 0, "Relay Open";
      logical_value, 1, "Relay Closed";
   }

   WantedRelayCoding {
      logical_value, 0, "Default";
      logical_value, 1, "Open Relay";
    logical_value, 2, "Close Relay";
   }

   CamperModeCoding {
      logical_value, 0, "Inactive";
      logical_value, 1, "Active";
    logical_value, 2, "Conditions not Correct";
    logical_value, 3, "Faulty";
   }

   CamperModeBCoding {
      logical_value, 0, "Inactive";
      logical_value, 1, "Active";
   }

   BattSOCCoding {
      physical_value, 0, 100, 1, 0, "%";
   }

   RelaySOCSourceCoding {
      logical_value, 0, "SoC from BMS";
      logical_value, 1, "Estimated From VBatt";
   }

   EcrmLogicCoding {
      logical_value, 0xA5, "Check Diagnostics";
   }

   SplitChargeRuleCoding {
      logical_value, 1, "Over Temperature";
    logical_value, 2, "Load Shed";
      logical_value, 3, "Protect Crank Battery (Engine Run)";
    logical_value, 4, "Protect Crank Battery (Engine Off)";
    logical_value, 5, "End Of Life Isolate Aux Battery";
    logical_value, 6, "Protect CCP";
    logical_value, 7, "Protect Aux Battery (Over Voltage)";
    logical_value, 8, "Allow Aux Charger";
    logical_value, 9, "Protect Aux Battery (CCP)";
    logical_value, 10, "Protect Aux Battery (Low SoC)";
    logical_value, 11, "Allow Power with Ignition Off (Utility)";
    logical_value, 12, "Allow Power with Ignition Off (Camper)";
    logical_value, 13, "Alternator Assist (Engine Run)";
    logical_value, 14, "BCM Relay Operation";
    logical_value, 15, "Disable Camper functionality in drive mode";
    logical_value, 0, "Normal Operating Conditions";
   }

   SFB_UpdateCoding {
     logical_value, 0, "Normal Mode";
     logical_value, 1, "Activate SFB WiFi";
   }

   HandbrakeCoding {
     logical_value, 0, "Handbrake Off";
     logical_value, 1, "Handbrake On";
   }

    LocalEpochCoding {
    physical_value, 0, 4294967296, 1, 0, "sec since 1970" ;
  }
}

Signal_representation {
  AhFlagCoding: BSBattSOC_AhFlag ;
  AutoStopCurrentEstCoding: AutoStopCurrentEst ;
  BSAutoDiagResetCounterCoding: BSAutoDiagResetCounter ;
  BSBattCurrentCoding: BSBattCurrent ;
  BSBattCurrentECOSCoding: BSBattCurrentECOS ;
  BSBattKoLCurrentCoding: BSBattKoLCurrent ;
  BSBattOCVCoding: BSBattOCV ;
  BSBattQCapAhLINCoding: BSBattQCapAhLIN, BSBattQCapAhTNom, BSBattSOHLAM, BSBattSOHSUL ;
  BSBattQDchQDCnCoding: BSBattQDchQDCn ;
  BSBattQDeltaRideAhLINCoding: BSBattQDeltaRideAhLIN ;
  BSBattRiCoding: BSBattRiTNom, BSBattRi, BSBattRi_25C ;
  BSBattRiStatusCoding: BSBattRiTNomStatus, BSBattRiStatus ;
  BSBattSOCCoding: BSBattSOC_Actual, BSBattSOC_EEM_Function, SOCWakeUpValue ;
  BSBattSOCRecalUsedCoding: BSBattSOCRecalUsed ;
  BSBattSOCStatusCoding: BSBattSOCStatus ;
  BSBattSOF_I_WCCCoding: BSBattSOF_I_WCC ;
  BSBattSOF_V_WCCCoding: BSBattSOF_V_WCC ;
  BSBattSOHLAMStatusCoding: BSBattSOHLAMStatus ;
  BSBattSOHSULStatusCoding: BSBattSOHSULStatus ;
  BSBattTSOFQDCoding: BSBattLastSOCRecal, BSBattTSOFQD, BSBattTSOHQD ;
  BSBattTSOFWCCCoding: BSBattTSOFWCC, BSBattTSOHWCC, BSCrankTimer ;
  BSBattTempCoding: BSBattTemp, BSBattSensorTemp ;
  BSBattTimeInServiceCoding: BSBattTimeInService ;
  BSBattVSOFCCCCoding: BSCurrentLoadResponse, BSBattVSOFCCC, BSBattVSOHCCC, BSBattVSOHCCC_50 ;
  BSBattVoltageCoding: BSBattVoltage ;
  BSBattVoltageECOSCoding: BSBattVoltageECOS ;
  BSBatt_Ah_QDCoding: BSBatt_Ah_QD ;
  BSBatt_Ah_QD_TBCoding: BSBatt_Ah_QD_TB ;
  BSBatt_Ah_QD_TimerCoding: BSBatt_Ah_QD_Timer ;
  BSBatt_Batt_Off_ASIL_Encoding: BSBatt_Batt_Off_ASIL ;
  BSBatt_Current_ASIL_Encoding: BSBatt_Current_ASIL ;
  BSBatt_I_QDCoding: BSBatt_I_QD ;
  BSBatt_Ri_ASIL_Encoding: BSBatt_Ri_ASIL ;
  BSBatt_Ri_Error_ASIL_Encoding: BSBatt_Ri_Error_ASIL ;
  BSBatt_SOF_ASIL_Encoding: BSBatt_SOF_ASIL ;
  BSBatt_SOF_Error_ASIL_Encoding: BSBatt_SOF_Error_ASIL ;
  BSBatt_Voltage_ASIL_Encoding: BSBatt_Voltage_ASIL ;
  BSBlindChargeFlagCoding: BSBattSOC_BlindChargeFlag, BSBlindChargeFlag ;
  BSConsistencyFaultCoding: BSBattSOC_ConsistencyFlag ;
  BSCrankCurrentCoding: BSCrankCurrent ;
  BSCrankVoltageCoding: BSBattUc0minAged, BSBattUc0maxAged, BSCrankVoltage ;
  BSDiagResetCoding: BSDiagReset ;
  BSDiagResetFlagCoding: BSBattSOC_BSDiagResetFlag ;
  BSFaultFlagCoding: BSBattSOC_BSFaultFlag ;
  BSFaultLINCoding: BSFaultLIN ;
  BSGassingRateCoding: BSGassingRate ;
  BSModeCoding: BSMode ;
  BSPowerOnJustOccuredCoding: BSPowerOnJustOccured ;
  BSShortedCellCoding: BSShortedCell ;
  BSStratificationCoding: BSStratification, BSIcing, BSConsistencyFault ;
  BSWaterLossCoding: BSWaterLoss ;
  BattNormAcidCapacityCoding: BatteryNormAcidCapacity ;
  BatteryCCACoding: BatteryCCA ;
  BatteryCapacityCoding: BatteryCapacity ;
  BatteryDesignCoding: BatteryDesign ;
  BatteryParametersFlagCoding: BSBattSOC_BatteryParameters ;
  BatterySizeCoding: BatterySize ;
  BatteryUC0maxCoding: BatteryUC0max ;
  CnCoding: BSBattQChaRideCN, BSBattQDchRideCn, BSBattQDchActCn ;
  CurrentLoadDurationCoding: CurrentLoadDuration ;
  CurrentLoadMagnitudeCoding: CurrentLoadMagnitude ;
  FullChrgDetectedCoding: BSBattFullChargeDetected ;
  IgnKeyPositionCoding: IgnKeyPosition ;
  LINStatus_ET: BMSLINStatus ;
  POI_SOC_CalCoding: POI_SOC_Cal ;
  PORFlagCoding: BSBattSOC_PORFlag ;
  Ri_25CCoding: Ri_25C_95, Ri_25C_75, Ri_25C_55, Ri_25C_45, Ri_25C_35, Ri_25C_25, Ri_25C_15 ;
  SleepModeCoding: SleepMode ;
  StarterResistanceCoding: StarterResistanceCCC, StarterResistanceWCC, StarterResistanceIQD ;
  TransportFlagCoding: BSBattSOC_TransportFlag ;

  AhFlag_BMS2_Coding: BSBatt2SOC_AhFlag ;
// Signal_representation of BMS2 can also be combined with Signal_representation of primary BMS
  AutoStopCurrentEst_BMS2_Coding: AutoStopCurrentEst_BMS2 ;
  BS2AutoDiagResetCounterCoding: BS2AutoDiagResetCounter ;
  BSBatt2CurrentCoding: BSBatt2Current ;
  BSBatt2CurrentECOSCoding: BSBatt2CurrentECOS ;
  BSBatt2KoLCurrentCoding: BSBatt2KoLCurrent ;
  BSBatt2OCVCoding: BSBatt2OCV ;
  BSBatt2QCapAhLINCoding: BSBatt2QCapAhLIN, BSBatt2QCapAhTNom, BSBatt2SOHLAM, BSBatt2SOHSUL ;
  BSBatt2QDchQDCnCoding: BSBatt2QDchQDCn ;
  BSBatt2QDeltaRideAhLINCoding: BSBatt2QDeltaRideAhLIN ;
  BSBatt2RiCoding: BSBatt2RiTNom, BSBatt2Ri, BSBatt2Ri_25C ;
  BSBatt2RiStatusCoding: BSBatt2RiTNomStatus, BSBatt2RiStatus ;
  BSBatt2SOCCoding: BSBatt2SOC_Actual, BSBatt2SOC_EEM_Function, SOCWakeUpValue ;
  BSBatt2SOCRecalUsedCoding: BSBatt2SOCRecalUsed ;
  BSBatt2SOCStatusCoding: BSBatt2SOCStatus ;
  BSBatt2SOF_I_WCCCoding: BSBatt2SOF_I_WCC ;
  BSBatt2SOF_V_WCCCoding: BSBatt2SOF_V_WCC ;
  BSBatt2SOHLAMStatusCoding: BSBatt2SOHLAMStatus ;
  BSBatt2SOHSULStatusCoding: BSBatt2SOHSULStatus ;
  BSBatt2TSOFQDCoding: BSBatt2LastSOCRecal, BSBatt2TSOFQD, BSBatt2TSOHQD ;
  BSBatt2TSOFWCCCoding: BSBatt2TSOFWCC, BSBatt2TSOHWCC, BS2CrankTimer ;
  BSBatt2TempCoding: BSBatt2Temp, BSBatt2SensorTemp ;
  BSBatt2TimeInServiceCoding: BSBatt2TimeInService ;
  BSBatt2VSOFCCCCoding: BS2CurrentLoadResponse, BSBatt2VSOFCCC, BSBatt2VSOHCCC, BSBatt2VSOHCCC_50 ;
  BSBatt2VoltageCoding: BSBatt2Voltage ;
  BSBatt2VoltageECOSCoding: BSBatt2VoltageECOS ;
  BSBatt2_Ah_QDCoding: BSBatt2_Ah_QD ;
  BSBatt2_Ah_QD_TBCoding: BSBatt2_Ah_QD_TB ;
  BSBatt2_Ah_QD_TimerCoding: BSBatt2_Ah_QD_Timer ;
  BSBatt2_I_QDCoding: BSBatt2_I_QD ;
  BS2BlindChargeFlagCoding: BSBatt2SOC_BlindChargeFlag, BS2BlindChargeFlag ;
  BS2ConsistencyFaultCoding: BSBatt2SOC_ConsistencyFlag ;
  BS2CrankCurrentCoding: BS2CrankCurrent ;
  BS2CrankVoltageCoding: BSBatt2Uc0minAged, BSBatt2Uc0maxAged, BS2CrankVoltage ;
  BS2DiagResetCoding: BS2DiagReset ;
  BS2DiagResetFlagCoding: BSBatt2SOC_BSDiagResetFlag ;
  BS2FaultFlagCoding: BSBatt2SOC_BSFaultFlag ;
  BS2FaultLINCoding: BS2FaultLIN ;
  BS2GassingRateCoding: BS2GassingRate ;
  BS2ModeCoding: BS2Mode ;
  BS2PowerOnJustOccuredCoding: BS2PowerOnJustOccured ;
  BS2ShortedCellCoding: BS2ShortedCell ;
  BS2StratificationCoding: BS2Stratification, BS2Icing, BS2ConsistencyFault ;
  BS2WaterLossCoding: BS2WaterLoss ;
  Batt2NormAcidCapacityCoding: Battery2NormAcidCapacity ;
  Battery2CCACoding: Battery2CCA ;
  Battery2CapacityCoding: Battery2Capacity ;
  Battery2DesignCoding: Battery2Design ;
  Battery2ParametersFlagCoding: BSBatt2SOC_BatteryParameters ;
  Battery2SizeCoding: Battery2Size ;
  Battery2UC0maxCoding: Battery2UC0max ;
  Cn_BMS2_Coding: BSBatt2QChaRideCN, BSBatt2QDchRideCn, BSBatt2QDchActCn ;
  CurrentLoadDuration_BMS2_Coding: CurrentLoadDuration_BMS2 ;
  CurrentLoadMagnitude_BMS2_Coding: CurrentLoadMagnitude_BMS2 ;
  FullChrgDetected_BMS2_Coding: BSBatt2FullChargeDetected ;
  IgnKeyPosition_BMS2_Coding: IgnKeyPosition_BMS2 ;
  LINStatus_ET_UCIM_UCIM2_Coding: UCIM_UCIM2_error_response_camper_st;
  LINStatus_ET_BMS2: BMS2LINStatus ;
  POI_SOC_Cal_BMS2_Coding: POI_SOC_Cal_BMS2 ;
  PORFlag_BMS2_Coding: BSBatt2SOC_PORFlag ;
  Ri_25C_Battery2_Coding: Ri_25C_95_Battery2, Ri_25C_75_Battery2, Ri_25C_55_Battery2, Ri_25C_45_Battery2, Ri_25C_35_Battery2, Ri_25C_25_Battery2, Ri_25C_15_Battery2 ;
  SleepMode_BMS2_Coding: SleepMode_BMS2 ;
  StarterResistance_BMS2_Coding: StarterResistanceCCC_BMS2, StarterResistanceWCC_BMS2, StarterResistanceIQD_BMS2 ;
  TransportFlag_BMS2_Coding: BSBatt2SOC_TransportFlag ;

   FuseStateCoding: FuseState1,
                                 FuseState2,
                                 FuseState3,
                                 FuseState4,
                                 FuseState5,
                                 FuseState6,
                                 FuseState7,
                                 FuseState8;
   InputStateCoding: InputPin1,
                                 InputPin2,
                                 InputPin3,
                                 InputPin4,
                                 InputPin5,
                                 InputPin6,
                                 InputPin7,
                                 InputPin8;
   RelayStateCoding: EcrmRelayState,
                                 CcpRelayState;
   CamperModeCoding: CamperMode_D_Stat;
   CamperModeBCoding: CamperMode_B_RQ;
   SplitChargeRuleCoding: SplitChargeRule;
   BattSOCCoding: BatterySocCrank,
                                 BatterySocAux1,
                                 BatterySocAux2;
   RelaySOCSourceCoding: BatterySocCrankSource,
                                 BatterySocAux1Source,
                                 BatterySocAux2Source;
   EcrmLogicCoding: EcrmLogicState;
   SoftButtonCoding: Soft_Button1,
                                 Soft_Button2,
                                 Soft_Button3,
                                 Soft_Button4,
                                 Soft_Button5,
                                 Soft_Button6,
                                 Soft_Button7,
                                 Soft_Button8,
                 CTS_Power;
   WantedRelayCoding: ECRS_Relay, CCP_Relay;
   SFB_UpdateCoding: SFB_Update;
   HandbrakeCoding: Handbrake;
   LocalEpochCoding: LocalEpoch;

}
